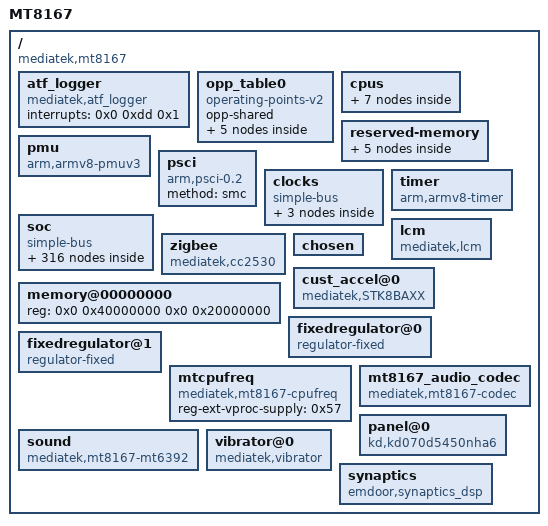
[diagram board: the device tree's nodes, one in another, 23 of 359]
/dts-v1/;

/ {
	model = "MT8167";
	compatible = "mediatek,mt8167";
	interrupt-parent = <0x1>;
	#address-cells = <0x2>;
	#size-cells = <0x2>;

	atf_logger {
		compatible = "mediatek,atf_logger";
		interrupts = <0x0 0xdd 0x1>;
	};

	opp_table0 {
		compatible = "operating-points-v2";
		opp-shared;
		linux,phandle = <0x7>;
		phandle = <0x7>;

		opp00 {
			opp-hz = <0x0 0x23a4c180>;
			opp-microvolt = <0x118c30>;
		};

		opp01 {
			opp-hz = <0x0 0x2c8df1e0>;
			opp-microvolt = <0x118c30>;
		};

		opp02 {
			opp-hz = <0x0 0x3dfd2400>;
			opp-microvolt = <0x124f80>;
		};

		opp03 {
			opp-hz = <0x0 0x47498300>;
			opp-microvolt = <0x1312d0>;
		};

		opp04 {
			opp-hz = <0x0 0x4d7c6d00>;
			opp-microvolt = <0x13d620>;
		};
	};

	cpus {
		#address-cells = <0x1>;
		#size-cells = <0x0>;

		cpu@0 {
			device_type = "cpu";
			compatible = "arm,cortex-a53";
			reg = <0x0>;
			enable-method = "psci";
			cpu-idle-states = <0x2 0x2 0x3 0x3 0x3>;
			clocks = <0x4 0x0 0x5 0x8 0x6 0x0>;
			clock-names = "cpu", "intermediate", "armpll";
			operating-points-v2 = <0x7>;
			clock-frequency = "M|m";
			proc-supply = <0x8>;
			linux,phandle = <0x9>;
			phandle = <0x9>;
		};

		cpu@1 {
			device_type = "cpu";
			compatible = "arm,cortex-a53";
			reg = <0x1>;
			enable-method = "psci";
			cpu-idle-states = <0x2 0x2 0x3 0x3 0x3>;
			clocks = <0x4 0x0 0x5 0x8 0x6 0x0>;
			clock-names = "cpu", "intermediate", "armpll";
			operating-points-v2 = <0x7>;
			clock-frequency = "M|m";
			proc-supply = <0x8>;
			linux,phandle = <0xa>;
			phandle = <0xa>;
		};

		cpu@2 {
			device_type = "cpu";
			compatible = "arm,cortex-a53";
			reg = <0x2>;
			enable-method = "psci";
			cpu-idle-states = <0x2 0x2 0x3 0x3 0x3>;
			clocks = <0x4 0x0 0x5 0x8 0x6 0x0>;
			clock-names = "cpu", "intermediate", "armpll";
			operating-points-v2 = <0x7>;
			clock-frequency = "M|m";
			proc-supply = <0x8>;
			linux,phandle = <0xb>;
			phandle = <0xb>;
		};

		cpu@3 {
			device_type = "cpu";
			compatible = "arm,cortex-a53";
			reg = <0x3>;
			enable-method = "psci";
			cpu-idle-states = <0x2 0x2 0x3 0x3 0x3>;
			clocks = <0x4 0x0 0x5 0x8 0x6 0x0>;
			clock-names = "cpu", "intermediate", "armpll";
			operating-points-v2 = <0x7>;
			clock-frequency = "M|m";
			proc-supply = <0x8>;
			linux,phandle = <0xc>;
			phandle = <0xc>;
		};

		idle-states {
			entry-method = "arm,psci";

			cpu-sleep-0-0 {
				compatible = "arm,idle-state";
				arm,psci-suspend-param = <0x10000>;
				entry-latency-us = <0x258>;
				exit-latency-us = <0x258>;
				min-residency-us = <0x4b0>;
				linux,phandle = <0x3>;
				phandle = <0x3>;
			};

			cluster-sleep-0 {
				compatible = "arm,idle-state";
				arm,psci-suspend-param = <0x2010000>;
				entry-latency-us = <0x320>;
				exit-latency-us = <0x3e8>;
				min-residency-us = <0x7d0>;
				linux,phandle = <0x2>;
				phandle = <0x2>;
			};
		};
	};

	reserved-memory {
		#address-cells = <0x2>;
		#size-cells = <0x2>;
		ranges;

		atf-reserved-memory@43000000 {
			compatible = "mediatek,mt8167-atf-reserved-memory";
			no-map;
			reg = <0x0 0x43000000 0x0 0x30000>;
		};

		ram_console-reserved-memory@44400000 {
			compatible = "mediatek,ram_console";
			reg = <0x0 0x44400000 0x0 0x10000>;
		};

		pstore-reserved-memory@44410000 {
			compatible = "mediatek,pstore";
			reg = <0x0 0x44410000 0x0 0xe0000>;
		};

		minirdump-reserved-memory@444f0000 {
			compatible = "mediatek,minirdump";
			reg = <0x0 0x444f0000 0x0 0x10000>;
		};

		consys-reserve-memory {
			compatible = "mediatek,consys-reserve-memory";
			no-map;
			size = <0x0 0x200000>;
			alignment = <0x0 0x200000>;
		};
	};

	pmu {
		compatible = "arm,armv8-pmuv3";
		interrupts = <0x0 0x4 0x8 0x0 0x5 0x8 0x0 0x6 0x8 0x0 0x7 0x8>;
		interrupt-affinity = <0x9 0xa 0xb 0xc>;
	};

	psci {
		compatible = "arm,psci-0.2";
		method = "smc";
	};

	clocks {
		#address-cells = <0x2>;
		#size-cells = <0x2>;
		compatible = "simple-bus";
		ranges;

		clk26m {
			compatible = "fixed-clock";
			#clock-cells = <0x0>;
			clock-frequency = <0x18cba80>;
		};

		clk32k {
			compatible = "fixed-clock";
			#clock-cells = <0x0>;
			clock-frequency = <0x7d00>;
			linux,phandle = <0xe>;
			phandle = <0xe>;
		};

		dummy26m {
			compatible = "fixed-clock";
			clock-frequency = <0x18cba80>;
			#clock-cells = <0x0>;
		};
	};

	timer {
		compatible = "arm,armv8-timer";
		interrupt-parent = <0xd>;
		interrupts = <0x1 0xd 0xf08 0x1 0xe 0xf08 0x1 0xb 0xf08 0x1 0xa 0xf08>;
		clock-frequency = <0xc65d40>;
	};

	soc {
		#address-cells = <0x2>;
		#size-cells = <0x2>;
		compatible = "simple-bus";
		ranges;

		chipid@08000000 {
			compatible = "mediatek,chipid";
			reg = <0x0 0x8000000 0x0 0x4 0x0 0x8000004 0x0 0x4 0x0 0x8000008 0x0 0x4 0x0 0x800000c 0x0 0x4>;
		};

		topckgen@10000000 {
			compatible = "mediatek,mt8167-topckgen", "syscon";
			reg = <0x0 0x10000000 0x0 0x1000>;
			#clock-cells = <0x1>;
			linux,phandle = <0x5>;
			phandle = <0x5>;
		};

		infracfg@10001000 {
			compatible = "mediatek,mt8167-infracfg", "syscon";
			reg = <0x0 0x10001000 0x0 0x1000>;
			#clock-cells = <0x1>;
			linux,phandle = <0x4>;
			phandle = <0x4>;
		};

		btcvsd@10001000 {
			compatible = "mediatek,audio_bt_cvsd";
			offset = <0xc00 0x2 0xfd0 0xfd4 0xfd8>;
			reg = <0x0 0x10001000 0x0 0x1000 0x0 0x18000000 0x0 0x10000 0x0 0x18080000 0x0 0x8000>;
			interrupts = <0x0 0xc2 0x8>;
		};

		mt_soc_btcvsd_rx_pcm@10001000 {
			compatible = "mediatek,mt_soc_btcvsd_rx_pcm";
		};

		mt_soc_btcvsd_tx_pcm@10001000 {
			compatible = "mediatek,mt_soc_btcvsd_tx_pcm";
		};

		syscfg_pctl_a@10005000 {
			compatible = "mediatek,mt8167-pctl-a-syscfg", "syscon";
			reg = <0x0 0x10005000 0x0 0x1000>;
			linux,phandle = <0xf>;
			phandle = <0xf>;
		};

		toprgu@10007000 {
			compatible = "mediatek,mt8167-wdt", "mediatek,mt6589-wdt";
			reg = <0x0 0x10007000 0x0 0x1000>;
			interrupts = <0x0 0xc6 0x2>;
			#reset-cells = <0x1>;
			linux,phandle = <0x47>;
			phandle = <0x47>;
		};

		timer@10008000 {
			compatible = "mediatek,mt8167-timer", "mediatek,mt6577-timer";
			reg = <0x0 0x10008000 0x0 0x1000>;
			interrupts = <0x0 0x84 0x8>;
			clocks = <0x5 0x32 0xe 0x5 0x5a>;
			clock-names = "clk13m", "clk32k", "bus";
		};

		pinctrl@10005000 {
			compatible = "mediatek,mt8167-pinctrl";
			reg = <0x0 0x1000b000 0x0 0x1000>;
			mediatek,pctl-regmap = <0xf>;
			pins-are-numbered;
			gpio-controller;
			#gpio-cells = <0x2>;
			interrupt-controller;
			#interrupt-cells = <0x2>;
			interrupts = <0x0 0x86 0x4>;
			pinctrl-names = "default";
			pinctrl-0 = <0x10>;
			linux,phandle = <0x12>;
			phandle = <0x12>;

			uart0gpiodefault {
				linux,phandle = <0x17>;
				phandle = <0x17>;
			};

			uart0_rx_set {
				linux,phandle = <0x18>;
				phandle = <0x18>;

				pins_cmd_dat {
					pinmux = <0x3e01>;
				};
			};

			uart0_rx_clear {
				linux,phandle = <0x19>;
				phandle = <0x19>;

				pins_cmd_dat {
					pinmux = <0x3e00>;
					slew-rate = <0x1>;
					output-high;
				};
			};

			uart0_tx_set {
				linux,phandle = <0x1a>;
				phandle = <0x1a>;

				pins_cmd_dat {
					pinmux = <0x3f01>;
				};
			};

			uart0_tx_clear {
				linux,phandle = <0x1b>;
				phandle = <0x1b>;

				pins_cmd_dat {
					pinmux = <0x3f00>;
					slew-rate = <0x1>;
					output-high;
				};
			};

			uart1gpiodefault {
				linux,phandle = <0x1c>;
				phandle = <0x1c>;
			};

			uart1_rx_set {
				linux,phandle = <0x1d>;
				phandle = <0x1d>;

				pins_cmd_dat {
					pinmux = <0x4001>;
				};
			};

			uart1_rx_clear {
				linux,phandle = <0x1e>;
				phandle = <0x1e>;

				pins_cmd_dat {
					pinmux = <0x4000>;
					slew-rate = <0x1>;
					output-high;
				};
			};

			uart1_tx_set {
				linux,phandle = <0x1f>;
				phandle = <0x1f>;

				pins_cmd_dat {
					pinmux = <0x4101>;
				};
			};

			uart1_tx_clear {
				linux,phandle = <0x20>;
				phandle = <0x20>;

				pins_cmd_dat {
					pinmux = <0x4100>;
					slew-rate = <0x1>;
					output-high;
				};
			};

			uart2gpiodefault {
				linux,phandle = <0x21>;
				phandle = <0x21>;
			};

			uart2_rx_set {
				linux,phandle = <0x22>;
				phandle = <0x22>;

				pins_cmd_dat {
					pinmux = <0x2201>;
				};
			};

			uart2_rx_clear {
				linux,phandle = <0x23>;
				phandle = <0x23>;

				pins_cmd_dat {
					pinmux = <0x2200>;
					slew-rate = <0x1>;
					output-high;
				};
			};

			uart2_tx_set {
				linux,phandle = <0x24>;
				phandle = <0x24>;

				pins_cmd_dat {
					pins = <0x2301>;
				};
			};

			uart2_tx_clear {
				linux,phandle = <0x25>;
				phandle = <0x25>;

				pins_cmd_dat {
					pinmux = <0x2300>;
					slew-rate = <0x1>;
					output-high;
				};
			};

			pinconf_default {
				linux,phandle = <0x10>;
				phandle = <0x10>;

				pins_cmd_dat {
					pinmux = <0xe03 0xf03 0x1003 0x4406 0x4506 0x4606 0x3701 0x3801 0x3901 0x1103>;
					bias-pull-up;
				};
			};

			audiodefault {
				linux,phandle = <0x5b>;
				phandle = <0x5b>;

				pins_cmd_dat {
					pins = <0x3200>;
					slew-rate = <0x1>;
					output-low;
				};
			};

			audexampon {
				linux,phandle = <0x5c>;
				phandle = <0x5c>;

				pins_cmd_dat {
					pins = <0x3200>;
					slew-rate = <0x1>;
					output-high;
				};
			};

			audexampoff {
				linux,phandle = <0x5d>;
				phandle = <0x5d>;

				pins_cmd_dat {
					pins = <0x3200>;
					slew-rate = <0x1>;
					output-low;
				};
			};

			audi2s1mode0 {
			};

			audi2s1mode1 {
			};

			pmicclkmode0 {
			};

			pmicclkmode1 {
			};

			dspdefault {
				linux,phandle = <0x5e>;
				phandle = <0x5e>;

				pins_cmd_dat {
					pins = <0x4700>;
					slew-rate = <0x1>;
					output-high;
				};
			};

			dsp_pins_rst_high {
				linux,phandle = <0x5f>;
				phandle = <0x5f>;

				pins_cmd_dat {
					pins = <0x4900>;
					slew-rate = <0x1>;
					output-high;
				};
			};

			dsp_pins_rst_low {
				linux,phandle = <0x60>;
				phandle = <0x60>;

				pins_cmd_dat {
					pins = <0x4900>;
					slew-rate = <0x1>;
					output-low;
				};
			};

			dsp_pins_pewr_high {
				linux,phandle = <0x61>;
				phandle = <0x61>;

				pins_cmd_dat {
					pins = <0x1400>;
					slew-rate = <0x1>;
					output-high;
				};
			};

			dsp_pins_pwr_low {
				linux,phandle = <0x62>;
				phandle = <0x62>;

				pins_cmd_dat {
					pins = <0x1400>;
					slew-rate = <0x1>;
					output-low;
				};
			};

			led_pins_pwr_high {
				linux,phandle = <0x63>;
				phandle = <0x63>;

				pins_cmd_dat {
					pins = <0x3300>;
					slew-rate = <0x1>;
					output-high;
				};
			};

			led_pins_pwr_low {
				linux,phandle = <0x64>;
				phandle = <0x64>;

				pins_cmd_dat {
					pins = <0x3300>;
					slew-rate = <0x1>;
					output-low;
				};
			};

			camdefault {
				linux,phandle = <0x3e>;
				phandle = <0x3e>;

				pins_cmd_dat {
					pinmux = <0x6601 0x6701 0x5e01 0x5f01 0x6001 0x6101 0x6201 0x6301>;
				};
			};

			cam0@0 {
				linux,phandle = <0x3f>;
				phandle = <0x3f>;

				pins_cmd_dat {
					pins = <0x3100>;
					slew-rate = <0x1>;
					output-low;
				};
			};

			cam0@1 {
				linux,phandle = <0x40>;
				phandle = <0x40>;

				pins_cmd_dat {
					pins = <0x3100>;
					slew-rate = <0x1>;
					output-high;
				};
			};

			cam0@2 {
				linux,phandle = <0x41>;
				phandle = <0x41>;

				pins_cmd_dat {
					pins = <0x3000>;
					slew-rate = <0x1>;
					output-low;
				};
			};

			cam0@3 {
				linux,phandle = <0x42>;
				phandle = <0x42>;

				pins_cmd_dat {
					pins = <0x3000>;
					slew-rate = <0x1>;
					output-high;
				};
			};

			cam1@0 {
				linux,phandle = <0x43>;
				phandle = <0x43>;

				pins_cmd_dat {
					pins = <0x3100>;
					slew-rate = <0x1>;
					output-low;
				};
			};

			cam1@1 {
				linux,phandle = <0x44>;
				phandle = <0x44>;

				pins_cmd_dat {
					pins = <0x3100>;
					slew-rate = <0x1>;
					output-high;
				};
			};

			cam1@2 {
				linux,phandle = <0x45>;
				phandle = <0x45>;

				pins_cmd_dat {
					pins = <0x2b00>;
					slew-rate = <0x1>;
					output-low;
				};
			};

			cam1@3 {
				linux,phandle = <0x46>;
				phandle = <0x46>;

				pins_cmd_dat {
					pins = <0x2b00>;
					slew-rate = <0x1>;
					output-high;
				};
			};

			cam_pin_mclk {

				pins_cmd_dat {
					pinmux = <0x6601 0x6701 0x5a02 0x5b02 0x5c02 0x5d02 0x5e02 0x5f02 0x6002 0x6102 0x6202 0x6302>;
				};
			};

			cam_pin_pclk {

				pins_cmd_dat {
					pins = <0x6701>;
				};
			};

			cam_pin_gpio90 {

				pins_cmd_dat {
					pins = <0x5a02>;
				};
			};

			cam_pin_gpio91 {

				pins_cmd_dat {
					pins = <0x5b02>;
				};
			};

			cam_pin_gpio92 {

				pins_cmd_dat {
					pins = <0x5c02>;
				};
			};

			cam_pin_gpio93 {

				pins_cmd_dat {
					pins = <0x5d02>;
				};
			};

			cam_pin_gpio94 {

				pins_cmd_dat {
					pins = <0x5e02>;
				};
			};

			cam_pin_gpio95 {

				pins_cmd_dat {
					pins = <0x5f02>;
				};
			};

			cam_pin_gpio96 {

				pins_cmd_dat {
					pins = <0x6002>;
				};
			};

			cam_pin_gpio97 {

				pins_cmd_dat {
					pins = <0x6102>;
				};
			};

			cam_pin_gpio98 {

				pins_cmd_dat {
					pins = <0x6202>;
				};
			};

			cam_pin_gpio99 {

				pins_cmd_dat {
					pins = <0x6302>;
				};
			};

			default {
				linux,phandle = <0x48>;
				phandle = <0x48>;
			};

			eint0default {
				linux,phandle = <0x4f>;
				phandle = <0x4f>;

				pins_cmd_dat {
					pins = <0x6400>;
					slew-rate = <0x0>;
					bias-disable;
				};
			};

			eint@0 {
				linux,phandle = <0x50>;
				phandle = <0x50>;

				pins_cmd_dat {
					pins = <0x6400>;
					slew-rate = <0x0>;
					bias-disable;
				};
			};

			eintoutput0 {
				linux,phandle = <0x51>;
				phandle = <0x51>;

				pins_cmd_dat {
					pins = <0x6400>;
					slew-rate = <0x1>;
					output-low;
				};
			};

			eintoutput1 {
				linux,phandle = <0x52>;
				phandle = <0x52>;

				pins_cmd_dat {
					pins = <0x6400>;
					slew-rate = <0x1>;
					output-high;
				};
			};

			rstoutput0 {
				linux,phandle = <0x53>;
				phandle = <0x53>;

				pins_cmd_dat {
					pins = <0x6500>;
					slew-rate = <0x1>;
					output-low;
				};
			};

			rstoutput1 {
				linux,phandle = <0x54>;
				phandle = <0x54>;

				pins_cmd_dat {
					pins = <0x6500>;
					slew-rate = <0x1>;
					output-high;
				};
			};

			hwen_high {
			};

			hwen_low {
			};

			gpslna@0 {
				linux,phandle = <0x49>;
				phandle = <0x49>;
			};

			gpslna@1 {
				linux,phandle = <0x4a>;
				phandle = <0x4a>;
			};

			gpslna@2 {
				linux,phandle = <0x4b>;
				phandle = <0x4b>;
			};

			hdmi_pins_default {
				linux,phandle = <0x35>;
				phandle = <0x35>;
			};

			hdmi_pins_hpd {
				linux,phandle = <0x36>;
				phandle = <0x36>;
			};

			i2c0@0 {
				linux,phandle = <0x26>;
				phandle = <0x26>;

				pins1 {
					pinmux = <0x3a01 0x3b01>;
					bias-disable;
				};
			};

			i2c1@0 {
				linux,phandle = <0x27>;
				phandle = <0x27>;

				pins1 {
					pinmux = <0x3401 0x3501>;
					bias-disable;
				};
			};

			i2c2@0 {
				linux,phandle = <0x28>;
				phandle = <0x28>;

				pins1 {
					pinmux = <0x3c01 0x3d01>;
					bias-disable;
				};
			};

			dpi_pins_default {
				linux,phandle = <0x59>;
				phandle = <0x59>;

				pins_cmd_dat {
					pinmux = <0x2302 0x1902 0x1802 0x2 0x2602 0x2702 0x2502 0x2402 0x2202 0x702 0x806 0x906 0xa06 0xb05 0xc05 0x102 0x202 0x302 0x402 0x502 0x602 0xd05>;
					drive-strength = <0x2>;
				};
			};

			mmc0default {
				linux,phandle = <0x31>;
				phandle = <0x31>;

				pins_cmd_dat {
					pinmux = <0x7801 0x7701 0x7601 0x7501 0x7101 0x7001 0x6f01 0x6e01 0x7301>;
					input-enable;
					bias-pull-up;
				};

				pins_clk {
					pinmux = <0x7401>;
					bias-pull-down;
				};

				pins_rst {
					pinmux = <0x7201>;
					bias-pull-up;
				};
			};

			mmc0@0 {
				linux,phandle = <0x32>;
				phandle = <0x32>;

				pins_cmd_dat {
					pinmux = <0x7801 0x7701 0x7601 0x7501 0x7101 0x7001 0x6f01 0x6e01 0x7301>;
					input-enable;
					drive-strength = <0x6>;
					bias-pull-up = <0x65>;
				};

				pins_clk {
					pinmux = <0x7401>;
					drive-strength = <0x8>;
					bias-pull-down = <0x66>;
				};

				pins_rst {
					pinmux = <0x7201>;
					bias-pull-up;
				};
			};

			drvvbus_init {
				linux,phandle = <0x2c>;
				phandle = <0x2c>;

				pins_cmd_dat {
					pins = <0x4100>;
					output-low;
				};
			};

			drvvbus_high {
				linux,phandle = <0x2e>;
				phandle = <0x2e>;

				pins_cmd_dat {
					pins = <0x4100>;
					slew-rate = <0x1>;
					output-high;
				};
			};

			drvvbus_low {
				linux,phandle = <0x2d>;
				phandle = <0x2d>;

				pins_cmd_dat {
					pins = <0x4100>;
					slew-rate = <0x1>;
					output-low;
				};
			};

			iddig_irq_init {
				linux,phandle = <0x2b>;
				phandle = <0x2b>;

				pins_cmd_dat {
					pins = <0x2902>;
					slew-rate = <0x0>;
					bias-pull-up = <0x0>;
				};
			};
		};

		dramco@10207000 {
			compatible = "mediatek,mt8167-dramco";
			reg = <0x0 0x10207000 0x0 0x1000>;
		};

		scpsys@10006000 {
			compatible = "mediatek,mt8167-scpsys", "syscon";
			#power-domain-cells = <0x1>;
			reg = <0x0 0x10006000 0x0 0x1000>;
			interrupts = <0x0 0x80 0x8 0x0 0x81 0x8 0x0 0x82 0x8 0x0 0x83 0x8>;
			infracfg = <0x4>;
			clocks = <0x5 0x82 0x5 0x83 0x5 0x42 0x5 0x7f>;
			clock-names = "axi_mfg", "mfg", "mm", "vdec";
			mediatek,pwrap-regmap = <0x11>;
			linux,phandle = <0x30>;
			phandle = <0x30>;
		};

		hacc@1000a000 {
			compatible = "mediatek,hacc";
			reg = <0x0 0x1000a000 0x0 0x1000>;
			clocks = <0x5 0x57 0x5 0x66>;
			clock-names = "main", "second";
		};

		pwrap@1000f000 {
			compatible = "mediatek,mt8167-pwrap";
			reg = <0x0 0x1000f000 0x0 0x1000>;
			reg-names = "pwrap";
			interrupts = <0x0 0xcc 0x8>;
			clocks = <0x5 0x5e 0x5 0x56>;
			clock-names = "spi", "wrap";
			status = "okay";
			linux,phandle = <0x11>;
			phandle = <0x11>;

			mt6392 {
				compatible = "mediatek,mt6392";
				mediatek,system-power-controller;
				interrupt-parent = <0x12>;
				interrupts = <0x1c 0x4>;
				interrupt-controller;
				#interrupt-cells = <0x2>;
				linux,phandle = <0x55>;
				phandle = <0x55>;

				mt6392keys {
					compatible = "mediatek,mt6392-keys";
					mediatek,pwrkey-code = <0x74>;
					mediatek,homekey-code = <0x72>;
					mediatek,long-press-mode = <0x0>;
					mediatek,long-press-duration = <0x0>;
				};

				mt6392pmic {
					compatible = "mediatek,mt6392-pmic";
				};

				mt6392regulator {
					compatible = "mediatek,mt6392-regulator";

					buck_vproc {
						regulator-name = "vproc";
						regulator-min-microvolt = <0xaae60>;
						regulator-max-microvolt = <0x149970>;
						regulator-ramp-delay = <0x30d4>;
						regulator-always-on;
						regulator-boot-on;
						linux,phandle = <0x8>;
						phandle = <0x8>;
					};

					buck_vsys {
						regulator-name = "vsys";
						regulator-min-microvolt = <0x155cc0>;
						regulator-max-microvolt = <0x2d95ec>;
						regulator-ramp-delay = <0x61a8>;
						regulator-always-on;
						regulator-boot-on;
					};

					buck_vcore {
						regulator-name = "vcore";
						regulator-min-microvolt = <0xaae60>;
						regulator-max-microvolt = <0x149970>;
						regulator-ramp-delay = <0x30d4>;
						regulator-always-on;
						regulator-boot-on;
						linux,phandle = <0x2a>;
						phandle = <0x2a>;
					};

					ldo_vxo22 {
						regulator-name = "vxo22";
						regulator-min-microvolt = <0x2191c0>;
						regulator-max-microvolt = <0x2191c0>;
						regulator-enable-ramp-delay = <0x6e>;
						regulator-always-on;
						regulator-boot-on;
					};

					ldo_vaud22 {
						regulator-name = "vaud22";
						regulator-min-microvolt = <0x1b7740>;
						regulator-max-microvolt = <0x2191c0>;
						regulator-enable-ramp-delay = <0x108>;
						regulator-always-on;
						regulator-boot-on;
					};

					ldo_vcama {
						regulator-name = "vcama";
						regulator-min-microvolt = <0x2ab980>;
						regulator-max-microvolt = <0x2ab980>;
						regulator-enable-ramp-delay = <0x108>;
						linux,phandle = <0x3a>;
						phandle = <0x3a>;
					};

					ldo_vaud28 {
						regulator-name = "vaud28";
						regulator-min-microvolt = <0x2ab980>;
						regulator-max-microvolt = <0x2ab980>;
						regulator-enable-ramp-delay = <0x108>;
						regulator-always-on;
						regulator-boot-on;
					};

					ldo_vadc18 {
						regulator-name = "vadc18";
						regulator-min-microvolt = <0x1b7740>;
						regulator-max-microvolt = <0x1b7740>;
						regulator-enable-ramp-delay = <0x108>;
						regulator-always-on;
						regulator-boot-on;
					};

					ldo_vcn35 {
						regulator-name = "vcn35";
						regulator-min-microvolt = <0x325aa0>;
						regulator-max-microvolt = <0x36ee80>;
						regulator-enable-ramp-delay = <0x108>;
						linux,phandle = <0x4d>;
						phandle = <0x4d>;
					};

					ldo_vio28 {
						regulator-name = "vio28";
						regulator-min-microvolt = <0x2ab980>;
						regulator-max-microvolt = <0x2ab980>;
						regulator-enable-ramp-delay = <0x108>;
						regulator-always-on;
						regulator-boot-on;
					};

					ldo_vusb {
						regulator-name = "vusb";
						regulator-min-microvolt = <0x325aa0>;
						regulator-max-microvolt = <0x325aa0>;
						regulator-enable-ramp-delay = <0x108>;
						regulator-always-on;
						regulator-boot-on;
						linux,phandle = <0x2f>;
						phandle = <0x2f>;
					};

					ldo_vmc {
						regulator-name = "vmc";
						regulator-min-microvolt = <0x1b7740>;
						regulator-max-microvolt = <0x325aa0>;
						regulator-enable-ramp-delay = <0x108>;
						regulator-boot-on;
					};

					ldo_vmch {
						regulator-name = "vmch";
						regulator-min-microvolt = <0x2dc6c0>;
						regulator-max-microvolt = <0x325aa0>;
						regulator-enable-ramp-delay = <0x108>;
						regulator-boot-on;
					};

					ldo_vemc3v3 {
						regulator-name = "vemc3v3";
						regulator-min-microvolt = <0x2dc6c0>;
						regulator-max-microvolt = <0x325aa0>;
						regulator-enable-ramp-delay = <0x108>;
						regulator-boot-on;
						linux,phandle = <0x33>;
						phandle = <0x33>;
					};

					ldo_vgp1 {
						regulator-name = "vgp1";
						regulator-min-microvolt = <0x124f80>;
						regulator-max-microvolt = <0x325aa0>;
						regulator-enable-ramp-delay = <0x108>;
						regulator-boot-on;
						linux,phandle = <0x4e>;
						phandle = <0x4e>;
					};

					ldo_vgp2 {
						regulator-name = "vgp2";
						regulator-min-microvolt = <0x124f80>;
						regulator-max-microvolt = <0x325aa0>;
						regulator-enable-ramp-delay = <0x108>;
						linux,phandle = <0x5a>;
						phandle = <0x5a>;
					};

					ldo_vcn18 {
						regulator-name = "vcn18";
						regulator-min-microvolt = <0x1b7740>;
						regulator-max-microvolt = <0x1b7740>;
						regulator-enable-ramp-delay = <0x108>;
						linux,phandle = <0x4c>;
						phandle = <0x4c>;
					};

					ldo_vcamaf {
						regulator-name = "vcamaf";
						regulator-min-microvolt = <0x325aa0>;
						regulator-max-microvolt = <0x325aa0>;
						regulator-enable-ramp-delay = <0x108>;
						regulator-always-on;
						regulator-boot-on;
						linux,phandle = <0x3d>;
						phandle = <0x3d>;
					};

					ldo_vm {
						regulator-name = "vm";
						regulator-min-microvolt = <0x12ebc0>;
						regulator-max-microvolt = <0x1535b0>;
						regulator-enable-ramp-delay = <0x108>;
						regulator-always-on;
						regulator-boot-on;
					};

					ldo_vio18 {
						regulator-name = "vio18";
						regulator-min-microvolt = <0x1b7740>;
						regulator-max-microvolt = <0x1b7740>;
						regulator-enable-ramp-delay = <0x108>;
						regulator-always-on;
						regulator-boot-on;
						linux,phandle = <0x34>;
						phandle = <0x34>;
					};

					ldo_vcamd {
						regulator-name = "vcamd";
						regulator-min-microvolt = <0x124f80>;
						regulator-max-microvolt = <0x1b7740>;
						regulator-enable-ramp-delay = <0x108>;
						linux,phandle = <0x3b>;
						phandle = <0x3b>;
					};

					ldo_vcamio {
						regulator-name = "vcamio";
						regulator-min-microvolt = <0x1b7740>;
						regulator-max-microvolt = <0x1b7740>;
						regulator-enable-ramp-delay = <0x108>;
						linux,phandle = <0x3c>;
						phandle = <0x3c>;
					};

					ldo_vm25 {
						regulator-name = "vm25";
						regulator-min-microvolt = <0x2625a0>;
						regulator-max-microvolt = <0x2625a0>;
						regulator-enable-ramp-delay = <0x108>;
						regulator-always-on;
						regulator-boot-on;
					};

					ldo_vefuse {
						regulator-name = "vefuse";
						regulator-min-microvolt = <0x1b7740>;
						regulator-max-microvolt = <0x1e8480>;
						regulator-enable-ramp-delay = <0x108>;
					};
				};

				pinctrl@c000 {
					compatible = "mediatek,mt6392-pinctrl";
					pins-are-numbered;
					gpio-controller;
					#gpio-cells = <0x2>;
				};

				typec {
					compatible = "mediatek,mt6392-typec";
					status = "disabled";
				};
			};
		};

		devapc_ao@10010000 {
			compatible = "mediatek,mt8167-devapc_ao";
			reg = <0x0 0x10010000 0x0 0x1000>;
		};

		keypad@10002000 {
			compatible = "mediatek,mt8167-keypad";
			reg = <0x0 0x10002000 0x0 0x1000>;
			interrupts = <0x0 0x95 0x2>;
			mediatek,kpd-key-debounce = <0x400>;
			mediatek,kpd-sw-pwrkey = <0x74>;
			mediatek,kpd-hw-pwrkey = <0x8>;
			mediatek,kpd-sw-rstkey = <0x0>;
			mediatek,kpd-hw-rstkey = <0x11>;
			mediatek,kpd-use-extend-type = <0x0>;
			mediatek,kpd-hw-map-num = <0x48>;
			mediatek,kpd-hw-init-map = <0x73 0x0 0x0 0x0 0x0 0x0 0x0 0x0 0x0 0x0 0x0 0x0 0x0 0x0 0x0 0x0 0x0 0x0 0x0 0x0 0x0 0x0 0x0 0x0 0x0 0x0 0x0 0x0 0x0 0x0 0x0 0x0 0x0 0x0 0x0 0x0 0x0 0x0 0x0 0x0 0x0 0x0 0x0 0x0 0x0 0x0 0x0 0x0 0x0 0x0 0x0 0x0 0x0 0x0 0x0 0x0 0x0 0x0 0x0 0x0 0x0 0x0 0x0 0x0 0x0 0x0 0x0 0x0 0x0 0x0 0x0 0x0>;
			mediatek,kpd-pwrkey-eint-gpio = <0x0>;
			mediatek,kpd-pwkey-gpio-din = <0x0>;
			mediatek,kpd-hw-dl-key0 = <0x0>;
			mediatek,kpd-hw-dl-key1 = <0x11>;
			mediatek,kpd-hw-dl-key2 = <0x8>;
			mediatek,kpd-hw-recovery-key = <0x11>;
			mediatek,kpd-hw-factory-key = <0x0>;
		};

		apmixedsys@10018000 {
			compatible = "mediatek,mt8167-apmixedsys", "syscon";
			reg = <0x0 0x10018000 0x0 0x710>;
			#clock-cells = <0x1>;
			linux,phandle = <0x6>;
			phandle = <0x6>;
		};

		fhctl@10018f00 {
			compatible = "mediatek,mt8167-fhctl";
			reg = <0x0 0x10018f00 0x0 0x100>;
		};

		accdet@1001b000 {
			compatible = "mediatek,mt8167-accdet";
			reg = <0x0 0x1001b000 0x0 0x1000>;
			status = "okay";
			mediatek,apmixedsys-regmap = <0x6>;
			interrupts-extended = <0x1 0x0 0x98 0x8 0x12 0x13 0x4>;
			interrupts = <0x13 0x4>;
			eint-debounce = <0x3e800>;
			accdet-gpio = <0x12 0x13 0x0>;
			accdet-mic-vol = <0x0>;
			headset-mode-setting = <0x500 0x500 0x1 0x1f0 0x800 0x800 0x20>;
			accdet-plugout-debounce = <0x14>;
			accdet-mic-mode = <0x1>;
			headset-four-key-threshold = <0x15e 0x1a4 0x352 0x5dc>;
		};

		mcucfg@10200000 {
			compatible = "mediatek,mt8167-mcucfg", "mediatek,mcucfg", "syscon";
			reg = <0x0 0x10200000 0x0 0x2000>;
		};

		intpol-controller@10200620 {
			compatible = "mediatek,mt8167-sysirq", "mediatek,mt6577-sysirq";
			interrupt-controller;
			#interrupt-cells = <0x3>;
			interrupt-parent = <0xd>;
			reg = <0x0 0x10200620 0x0 0x20>;
			linux,phandle = <0x1>;
			phandle = <0x1>;
		};

		emi@10205000 {
			compatible = "mediatek,mt8167-emi", "mediatek,emi";
			reg = <0x0 0x10205000 0x0 0x1000>;
			interrupts = <0x0 0x74 0x4>;
		};

		m4u@10203000 {
			cell-index = <0x0>;
			compatible = "mediatek,mt8167-m4u";
			reg = <0x0 0x10203000 0x0 0x1000>;
			mediatek,larbs = <0x13 0x14 0x15>;
			interrupts = <0x0 0x79 0x8>;
			#iommu-cells = <0x1>;
			linux,phandle = <0x56>;
			phandle = <0x56>;
		};

		sys_cirq@10202000 {
			compatible = "mediatek,mt8167-sys_cirq", "mediatek,mt6735-sys_cirq", "mediatek,sys_cirq";
			reg = <0x0 0x10202000 0x0 0x1000>;
			interrupts = <0x0 0xda 0x8>;
			mediatek,cirq_num = <0x93>;
			mediatek,spi_start_offset = <0x48>;
		};

		devapc@10204000 {
			compatible = "mediatek,mt8167-devapc";
			reg = <0x0 0x10204000 0x0 0x1000>;
			interrupts = <0x0 0x72 0x8>;
		};

		systracker@1020b000 {
			compatible = "mediatek,bus_dbg-v2";
			reg = <0x0 0x1020b000 0x0 0x1000>;
			interrupts = <0x0 0x7b 0x8>;
		};

		dramc_nao@10206000 {
			compatible = "mediatek,mt8167-dramc_nao", "mediatek,dramc_nao";
			reg = <0x0 0x10206000 0x0 0x1000>;
		};

		xo@10210000 {
			compatible = "mediatek,mt8167-xo";
			reg = <0x0 0x10210000 0x0 0x1000>;
			clocks = <0x5 0x7a 0x5 0x8c>;
			clock-names = "bsi", "rgbsi";
		};

		ddrphy@10211000 {
			compatible = "mediatek,mt8167-ddrphy", "mediatek,ddrphy";
			reg = <0x0 0x10211000 0x0 0x1000>;
		};

		gce@1020a000 {
			compatible = "mediatek,mt8167-gce";
			reg = <0x0 0x1020a000 0x0 0x1000>;
			interrupts = <0x0 0x7d 0x8 0x0 0x7e 0x8>;
			disp_mutex_reg = <0x14015000 0x1000>;
			g3d_config_base = <0x13000000 0x0 0xffff0000>;
			mmsys_config_base = <0x14000000 0x1 0xffff0000>;
			disp_dither_base = <0x14010000 0x2 0xffff0000>;
			mm_na_base = <0x14020000 0x3 0xffff0000>;
			imgsys_base = <0x15000000 0x4 0xffff0000>;
			vdec_gcon_base = <0x16000000 0x5 0xffff0000>;
			venc_gcon_base = <0x17000000 0x6 0xffff0000>;
			conn_peri_base = <0x18000000 0x7 0xffff0000>;
			topckgen_base = <0x10000000 0x8 0xffff0000>;
			kp_base = <0x10010000 0x9 0xffff0000>;
			scp_sram_base = <0x10020000 0xa 0xffff0000>;
			infra_na3_base = <0x10030000 0xb 0xffff0000>;
			infra_na4_base = <0x10040000 0xc 0xffff0000>;
			scp_base = <0x10050000 0xd 0xffff0000>;
			mcucfg_base = <0x10200000 0xe 0xffff0000>;
			gcpu_base = <0x1020d000 0xf 0xffff0000>;
			usb0_base = <0x11200000 0x10 0xffff0000>;
			usb_sif_base = <0x11210000 0x11 0xffff0000>;
			audio_base = <0x11220000 0x12 0xffff0000>;
			msdc0_base = <0x11230000 0x13 0xffff0000>;
			msdc1_base = <0x11240000 0x14 0xffff0000>;
			msdc2_base = <0x11250000 0x15 0xffff0000>;
			msdc3_base = <0x11260000 0x16 0xffff0000>;
			pwm_sw_base = <0x1100f000 0x63 0xfffff000>;
			mdp_rdma0_sof = <0x0>;
			mdp_rsz0_sof = <0x1>;
			mdp_rsz1_sof = <0x2>;
			mdp_tdshp_sof = <0x3>;
			mdp_wdma_sof = <0x4>;
			mdp_wrot_sof = <0x5>;
			disp_ovl0_sof = <0x6>;
			disp_rdma0_sof = <0x8>;
			disp_rdma1_sof = <0x9>;
			disp_wdma0_sof = <0xa>;
			disp_ccorr_sof = <0xb>;
			disp_color_sof = <0xc>;
			disp_aal_sof = <0xd>;
			disp_gamma_sof = <0xe>;
			disp_dither_sof = <0xf>;
			disp_ufoe_sof = <0x10>;
			disp_pwm0_sof = <0x11>;
			mdp_rdma0_frame_done = <0x12>;
			mdp_rsz0_frame_done = <0x13>;
			mdp_rsz1_frame_done = <0x14>;
			mdp_tdshp_frame_done = <0x15>;
			mdp_wdma_frame_done = <0x16>;
			mdp_wrot_write_frame_done = <0x17>;
			mdp_wrot_read_frame_done = <0x18>;
			disp_ovl0_frame_done = <0x19>;
			disp_rdma0_frame_done = <0x1b>;
			disp_rdma1_frame_done = <0x1c>;
			disp_wdma0_frame_done = <0x1d>;
			disp_ccorr_frame_done = <0x1e>;
			disp_color_frame_done = <0x1f>;
			disp_aal_frame_done = <0x20>;
			disp_gamma_frame_done = <0x21>;
			disp_dither_frame_done = <0x22>;
			disp_ufoe_frame_done = <0x23>;
			disp_dpi0_frame_done = <0x24>;
			disp_dpi1_frame_done = <0x25>;
			stream_done_0 = <0x26>;
			stream_done_1 = <0x27>;
			stream_done_2 = <0x28>;
			stream_done_3 = <0x29>;
			stream_done_4 = <0x2a>;
			stream_done_5 = <0x2b>;
			stream_done_6 = <0x2c>;
			stream_done_7 = <0x2d>;
			stream_done_8 = <0x2e>;
			stream_done_9 = <0x2f>;
			buf_underrun_event_0 = <0x30>;
			buf_underrun_event_1 = <0x31>;
			isp_frame_done_p2_1 = <0x42>;
			isp_frame_done_p2_0 = <0x43>;
			seninf_cam0_fifo_full = <0x49>;
			apxgpt2_count = <0x10008028>;
			clocks = <0x5 0x64 0x16 0x0 0x16 0x1 0x16 0x2 0x16 0x3 0x16 0x4 0x16 0x5 0x16 0x6 0x16 0x8 0x16 0x7>;
			clock-names = "MT_CG_INFRA_GCE", "MT_CG_DISP0_SMI_COMMON", "MT_CG_DISP0_SMI_LARB0", "MT_CG_DISP0_CAM_MDP", "MT_CG_DISP0_MDP_RDMA", "MT_CG_DISP0_MDP_RSZ0", "MT_CG_DISP0_MDP_RSZ1", "MT_CG_DISP0_MDP_TDSHP", "MT_CG_DISP0_MDP_WROT", "MT_CG_DISP0_MDP_WDMA";
		};

		interrupt-controller@10310000 {
			compatible = "arm,gic-400";
			interrupt-controller;
			#interrupt-cells = <0x3>;
			interrupt-parent = <0xd>;
			reg = <0x0 0x10310000 0x0 0x1000 0x0 0x10320000 0x0 0x1000 0x0 0x10340000 0x0 0x2000 0x0 0x10360000 0x0 0x2000>;
			interrupts = <0x1 0x9 0xf04>;
			linux,phandle = <0xd>;
			phandle = <0xd>;
		};

		btif_tx@11000380 {
			compatible = "mediatek,btif_tx";
			reg = <0x0 0x11000380 0x0 0x80>;
			interrupts = <0x0 0x5e 0x8>;
		};

		btif_rx@11000400 {
			compatible = "mediatek,btif_rx";
			reg = <0x0 0x11000400 0x0 0x80>;
			interrupts = <0x0 0x5f 0x8>;
		};

		nfi@11001000 {
			compatible = "mediatek,mt8167-nfi";
			reg = <0x0 0x11001000 0x0 0x1000>;
			interrupts = <0x0 0x57 0x8>;
			clocks = <0x5 0x63 0x5 0x49 0x5 0x48 0x5 0x8e 0x5 0x55 0x5 0x3a 0x5 0xad 0x5 0xac 0x5 0xce 0x5 0xcd 0x5 0xa1 0x5 0x31 0x5 0x9 0x5 0x11 0x5 0xf 0x5 0x15 0x5 0xa 0x5 0x12 0x5 0x10>;
			clock-names = "nfi_hclk", "nfiecc_bclk", "nfi_bclk", "nfi_rgecc", "nfi_2xclk", "nfi_1xclk", "nfi_1xpad_sel", "nfi_2xpad_sel", "nfiecc_sel", "nfiecc_csw_sel", "infra_ahb", "clk_26m", "main_d4", "main_d5", "main_d6", "main_d7", "main_d8", "main_d10", "main_d12";
			status = "disabled";
		};

		nfiecc@11002000 {
			compatible = "mediatek,mt8167-nfiecc";
			reg = <0x0 0x11002000 0x0 0x1000>;
			interrupts = <0x0 0x56 0x8>;
			status = "disabled";
		};

		auxadc@11003000 {
			compatible = "mediatek,mt8167-auxadc";
			reg = <0x0 0x11003000 0x0 0x1000>;
			interrupts = <0x0 0x4b 0x2>;
			clocks = <0x5 0x5f 0x5 0x47 0x5 0x51 0x5 0x60>;
			clock-names = "auxadc-main", "auxadc1", "auxadc2", "auxadc-tp";
			linux,phandle = <0x29>;
			phandle = <0x29>;
		};

		uart0@11005000 {
			cell-index = <0x0>;
			compatible = "mediatek,mt8167-uart";
			reg = <0x0 0x11005000 0x0 0x1000 0x0 0x11000480 0x0 0x80 0x0 0x11000500 0x0 0x80>;
			interrupts = <0x0 0x54 0x8 0x0 0x60 0x8 0x0 0x61 0x8>;
			clock-frequency = <0x18cba80>;
			clock-div = <0x1>;
			clocks = <0x5 0x4c 0x5 0x44>;
			clock-names = "uart0-main", "uart-apdma";
			pinctrl-names = "uart0_gpio_default", "uart0_rx_set", "uart0_rx_clear", "uart0_tx_set", "uart0_tx_clear";
			pinctrl-0 = <0x17>;
			pinctrl-1 = <0x18>;
			pinctrl-2 = <0x19>;
			pinctrl-3 = <0x1a>;
			pinctrl-4 = <0x1b>;
			status = "okay";
		};

		uart1@11006000 {
			cell-index = <0x1>;
			compatible = "mediatek,mt8167-uart", "mediatek,mt6577-uart";
			reg = <0x0 0x11006000 0x0 0x1000 0x0 0x11000580 0x0 0x80 0x0 0x11000600 0x0 0x80>;
			interrupts = <0x0 0x55 0x8 0x0 0x62 0x8 0x0 0x63 0x8>;
			clock-frequency = <0x18cba80>;
			clock-div = <0x1>;
			clocks = <0x5 0x4d>;
			clock-names = "uart1-main";
			pinctrl-names = "uart1_gpio_default", "uart1_rx_set", "uart1_rx_clear", "uart1_tx_set", "uart1_tx_clear";
			pinctrl-0 = <0x1c>;
			pinctrl-1 = <0x1d>;
			pinctrl-2 = <0x1e>;
			pinctrl-3 = <0x1f>;
			pinctrl-4 = <0x20>;
			status = "okay";
		};

		uart2@11007000 {
			cell-index = <0x2>;
			compatible = "mediatek,mt8167-uart";
			reg = <0x0 0x11007000 0x0 0x1000 0x0 0x11000980 0x0 0x80 0x0 0x11000a00 0x0 0x80>;
			interrupts = <0x0 0xd4 0x8 0x0 0x64 0x8 0x0 0x65 0x8>;
			clock-frequency = <0x18cba80>;
			clock-div = <0x1>;
			clocks = <0x5 0x79>;
			clock-names = "uart2-main";
			pinctrl-names = "uart2_gpio_default", "uart2_rx_set", "uart2_rx_clear", "uart2_tx_set", "uart2_tx_clear";
			pinctrl-0 = <0x21>;
			pinctrl-1 = <0x22>;
			pinctrl-2 = <0x23>;
			pinctrl-3 = <0x24>;
			pinctrl-4 = <0x25>;
			status = "disable";
		};

		pwm@11008000 {
			compatible = "mediatek,mt8167-pwm";
			reg = <0x0 0x11008000 0x0 0x1000>;
			interrupts = <0x0 0x4c 0x8>;
			clocks = <0x5 0x69 0x5 0x6a 0x5 0x6b 0x5 0x6c 0x5 0x6d 0x5 0x4b 0x5 0x68>;
			clock-names = "PWM1-main", "PWM2-main", "PWM3-main", "PWM4-main", "PWM5-main", "PWM-HCLK-main", "PWM-main";
		};

		i2c@11009000 {
			compatible = "mediatek,mt8167-i2c";
			reg = <0x0 0x11009000 0x0 0x90 0x0 0x11000180 0x0 0x80>;
			interrupts = <0x0 0x50 0x8>;
			clocks = <0x5 0x39 0x4 0x2 0x5 0x45 0x5 0x44>;
			clock-names = "main-source", "main-sel", "main", "dma";
			#address-cells = <0x1>;
			#size-cells = <0x0>;
			status = "okay";
			clock-div = <0x2>;
			pinctrl-names = "default";
			pinctrl-0 = <0x26>;

			lp8557_led@2c {
				compatible = "ti,lp8557-led";
				reg = <0x2c>;
			};

			cap_touch@40 {
				compatible = "mediatek,cap_touch";
				reg = <0x40>;
				interrupt-parent = <0x12>;
				interrupts = <0x64 0x2>;
				int-gpio = <0x12 0x64 0x0>;
				rst-gpio = <0x12 0x65 0x0>;
			};

			strobe_main@63 {
				compatible = "mediatek,strobe_main";
				reg = <0x63>;
			};
		};

		i2c@1100a000 {
			compatible = "mediatek,mt8167-i2c";
			reg = <0x0 0x1100a000 0x0 0x90 0x0 0x11000200 0x0 0x80>;
			interrupts = <0x0 0x51 0x8>;
			clocks = <0x5 0x39 0x4 0x3 0x5 0x46 0x5 0x44>;
			clock-names = "main-source", "main-sel", "main", "dma";
			#address-cells = <0x1>;
			#size-cells = <0x0>;
			status = "okay";
			clock-div = <0x2>;
			pinctrl-names = "default";
			pinctrl-0 = <0x27>;

			gsensor@18 {
				compatible = "mediatek,gsensor1";
				reg = <0x18>;
			};

			nuvoton@1c {
				compatible = "nuvoton,nau8540";
				reg = <0x1c>;
			};

			ad82584f@31 {
				compatible = "ESMT, ad82584f";
				reg = <0x31>;
			};

			sym827@60 {
				compatible = "silergy,sym827-regulator";
				reg = <0x60>;
				regulator-name = "vproc";
				regulator-min-microvolt = <0x927c0>;
				regulator-max-microvolt = <0x152bec>;
				regulator-enable-ramp-delay = <0x190>;
				regulator-ramp-delay = <0x208d>;
				regulator-always-on;
				vsel-gpio = <0x12 0x22 0x0>;
				linux,phandle = <0x57>;
				phandle = <0x57>;
			};
		};

		i2c@1100b000 {
			compatible = "mediatek,mt8167-i2c";
			reg = <0x0 0x1100b000 0x0 0x90 0x0 0x11000280 0x0 0x80>;
			interrupts = <0x0 0x52 0x8>;
			clocks = <0x5 0x39 0x4 0x4 0x5 0x52 0x5 0x44>;
			clock-names = "main-source", "main-sel", "main", "dma";
			#address-cells = <0x1>;
			#size-cells = <0x0>;
			status = "okay";
			clock-div = <0x2>;
			pinctrl-names = "default";
			pinctrl-0 = <0x28>;

			camera_sub_af@18 {
				compatible = "mediatek,camera_sub_af";
				reg = <0x18>;
			};

			kd_camera_hw2@30 {
				compatible = "mediatek,camera_sub";
				reg = <0x30>;
			};

			kd_camera_hw1@36 {
				compatible = "mediatek,camera_main";
				reg = <0x36>;
			};
		};

		spi@1100c000 {
			compatible = "mediatek,mt8167-spi";
			#address-cells = <0x1>;
			#size-cells = <0x0>;
			reg = <0x0 0x1100c000 0x0 0x1000>;
			interrupts = <0x0 0x68 0x8>;
			clocks = <0x5 0x1d 0x5 0xc8 0x5 0x59>;
			clock-names = "parent-clk", "sel-clk", "spi-clk";
			status = "disabled";
		};

		thermal@1100d000 {
			compatible = "mediatek,mt8167-thermal";
			reg = <0x0 0x1100d000 0x0 0x1000>;
			interrupts = <0x0 0x4d 0x8>;
			clocks = <0x5 0x43 0x5 0x5f>;
			clock-names = "therm", "auxadc";
			auxadc = <0x29>;
			apmixedsys = <0x6>;
			infracfg = <0x4>;
		};

		ptp_od@1100d000 {
			compatible = "mediatek,mt8167-ptp_od";
			reg = <0x0 0x1100d000 0x0 0x1000>;
			interrupts = <0x0 0x53 0x8>;
			vproc-supply = <0x8>;
			vcore-supply = <0x2a>;
		};

		btif@1100e000 {
			compatible = "mediatek,btif";
			reg = <0x0 0x1100e000 0x0 0x1000>;
			interrupts = <0x0 0x6b 0x8>;
			clocks = <0x5 0x4e 0x5 0x44>;
			clock-names = "btifc", "apdmac";
		};

		disp_pwm0@1100f000 {
			compatible = "mediatek,mt8167-disp_pwm";
			reg = <0x0 0x1100f000 0x0 0x1000>;
		};

		usb@11100000 {
			compatible = "mediatek,mt8167-usb20";
			reg = <0x0 0x11100000 0x0 0x10000 0x0 0x11110000 0x0 0x10000>;
			interrupts = <0x0 0x48 0x8>;
			mode = <0x2>;
			multipoint = <0x1>;
			dyn_fifo = <0x1>;
			soft_con = <0x1>;
			dma = <0x1>;
			num_eps = <0x10>;
			dma_channels = <0x8>;
			iddig_gpio = <0x12 0x29 0x2>;
			clocks = <0x5 0x28 0x5 0x78 0x5 0x4f 0x5 0x6e>;
			clock-names = "usbpll", "usbmcu", "usb", "icusb";
			pinctrl-names = "iddig_irq_init", "drvvbus_init", "drvvbus_low", "drvvbus_high";
			pinctrl-0 = <0x2b>;
			pinctrl-1 = <0x2c>;
			pinctrl-2 = <0x2d>;
			pinctrl-3 = <0x2e>;
			usb-power-supply = <0x2f>;
			status = "okay";
			drvvbus_gpio = <0x12 0x44 0x0>;
		};

		audio-controller@11140000 {
			compatible = "mediatek,mt8167-afe-pcm";
			reg = <0x0 0x11140000 0x0 0x1000 0x0 0x11141000 0x0 0x9000>;
			interrupts = <0x0 0x78 0x8>;
			clocks = <0x5 0x5b 0x5 0x95 0x5 0x96 0x5 0x97 0x5 0x98 0x5 0x99 0x5 0x9a 0x5 0x9b 0x5 0x9c 0x5 0x9d 0x5 0x8a 0x5 0x86 0x5 0x87 0x5 0x84 0x5 0x85 0x5 0xc0 0x5 0xc1 0x5 0xc2 0x5 0xc3 0x5 0xc4 0x5 0xc5 0x5 0xc6>;
			clock-names = "top_pdn_audio", "apll12_div0", "apll12_div1", "apll12_div2", "apll12_div3", "apll12_div4", "apll12_div4b", "apll12_div5", "apll12_div5b", "apll12_div6", "spdif_in", "engen1", "engen2", "aud1", "aud2", "i2s0_m_sel", "i2s1_m_sel", "i2s2_m_sel", "i2s3_m_sel", "i2s4_m_sel", "i2s5_m_sel", "spdif_b_sel";
			assigned-clocks = <0x5 0xbb 0x5 0xbc 0x5 0xbd 0x5 0xbe>;
			assigned-clock-parents = <0x5 0x29 0x5 0x2d 0x5 0x91 0x5 0x94>;
			mediatek,tdm-out-mode = <0x0>;
			linux,phandle = <0x58>;
			phandle = <0x58>;
		};

		clark@13000000 {
			compatible = "mediatek,mt8167-clark";
			reg = <0x0 0x13000000 0x0 0x80000 0x0 0x13ffe000 0x0 0x1000>;
			interrupts = <0x0 0xb9 0x8>;
			interrupt-names = "RGX";
			power-domains = <0x30 0x5>;
			clocks = <0x5 0xae 0x5 0xb9 0x5 0xba 0x5 0x83 0x5 0x82 0x5 0x3e 0x5 0x31 0x5 0x1e 0x5 0xc 0x5 0xa2>;
			clock-names = "mfg_mm_in_sel", "mfg_axi_in_sel", "mfg_slow_in_sel", "top_slow", "top_axi", "top_mm", "slow_clk26m", "bus_univpll_d24", "bus_mainpll_d11", "engine_csw_mux";
			clock-frequency = <0x17d78400>;
		};

		mfgcfg@13ffe000 {
			compatible = "mediatek,mt8167-mfgcfg", "syscon";
			reg = <0x0 0x13ffe000 0x0 0x1000>;
			#clock-cells = <0x1>;
		};

		mmc@11120000 {
			compatible = "mediatek,mt8167-mmc";
			reg = <0x0 0x11120000 0x0 0x1000>;
			interrupts = <0x0 0x4e 0x8>;
			clocks = <0x5 0x53 0x5 0xa1 0x5 0xd9>;
			clock-names = "source", "hclk", "source_cg";
			status = "okay";
			pinctrl-names = "default", "state_uhs";
			pinctrl-0 = <0x31>;
			pinctrl-1 = <0x32>;
			bus-width = <0x8>;
			max-frequency = <0xbebc200>;
			cap-mmc-highspeed;
			mmc-hs200-1_8v;
			cap-mmc-hw-reset;
			vmmc-supply = <0x33>;
			vqmmc-supply = <0x34>;
			non-removable;
		};

		mmc@11130000 {
			compatible = "mediatek,mt8167-mmc";
			reg = <0x0 0x11130000 0x0 0x1000>;
			interrupts = <0x0 0x4f 0x8>;
			clocks = <0x5 0x54 0x5 0xa1 0x5 0xda>;
			clock-names = "source", "hclk", "source_cg";
			status = "disabled";
		};

		audiotop@11140000 {
			compatible = "mediatek,mt8167-audiotop", "syscon";
			reg = <0x0 0x11140000 0x0 0x1000>;
			#clock-cells = <0x1>;
		};

		sdio@11170000 {
			compatible = "mediatek,mt8167-sdio";
			reg = <0x0 0x11170000 0x0 0x1000>;
			interrupts = <0x0 0x6d 0x8>;
			clocks = <0x5 0x61 0x5 0xdb>;
			clock-names = "sdio-bus", "sdio-src";
			status = "disabled";
		};

		usb@11190000 {
			compatible = "mediatek,mt8167-usb11";
			cell-index = <0x1>;
			reg = <0x0 0x11190000 0x0 0x10000 0x0 0x11110000 0x0 0x10000>;
			interrupts = <0x0 0xd2 0x8>;
			mode = <0x2>;
			multipoint = <0x1>;
			dyn_fifo = <0x1>;
			soft_con = <0x1>;
			dma = <0x1>;
			num_eps = <0x8>;
			dma_channels = <0x4>;
		};

		mmsys@14000000 {
			compatible = "mediatek,mt8167-mmsys", "syscon";
			reg = <0x0 0x14000000 0x0 0x1000>;
			#clock-cells = <0x1>;
			linux,phandle = <0x16>;
			phandle = <0x16>;
		};

		mdp_rdma@14001000 {
			compatible = "mediatek,mt8167-mdp_rdma";
			reg = <0x0 0x14001000 0x0 0x1000>;
			interrupts = <0x0 0x9a 0x8>;
		};

		mdp_rsz0@14002000 {
			compatible = "mediatek,mt8167-mdp_rsz0";
			reg = <0x0 0x14002000 0x0 0x1000>;
			interrupts = <0x0 0x9b 0x8>;
		};

		mdp_rsz1@14003000 {
			compatible = "mediatek,mt8167-mdp_rsz1";
			reg = <0x0 0x14003000 0x0 0x1000>;
			interrupts = <0x0 0x9c 0x8>;
		};

		mdp_wdma@14004000 {
			compatible = "mediatek,mt8167-mdp_wdma";
			reg = <0x0 0x14004000 0x0 0x1000>;
			interrupts = <0x0 0x9e 0x8>;
		};

		mdp_wrot@14005000 {
			compatible = "mediatek,mt8167-mdp_wrot";
			reg = <0x0 0x14005000 0x0 0x1000>;
			interrupts = <0x0 0x9f 0x8>;
		};

		mdp_tdshp@14006000 {
			compatible = "mediatek,mdp_tdshp";
			reg = <0x0 0x14006000 0x0 0x1000>;
			interrupts = <0x0 0x9d 0x8>;
		};

		mt8167-dispsys {
			compatible = "mediatek,mt8167-dispsys";
			mediatek,larb = <0x13>;
			clocks = <0x16 0x9 0x16 0xa 0x16 0xb 0x16 0xc 0x16 0xd 0x16 0xe 0x16 0xf 0x16 0x10 0x16 0x11 0x16 0x12 0x16 0x13 0x5 0x3c 0x16 0x14 0x16 0x15 0x16 0x16 0x16 0x17 0x16 0x19 0x16 0x18 0x16 0x1a 0x16 0x1b 0x16 0x1d 0x16 0x1c 0x5 0x33 0x5 0x40 0x5 0x80 0x5 0xb7 0x6 0x7 0x5 0x25 0x5 0x26 0x5 0x27 0x5 0x81 0x5 0xb8 0x6 0x6 0x5 0x35 0x5 0x36 0x5 0x37 0x5 0x38 0x5 0xc7 0x5 0x1d>;
			clock-names = "MMSYS_CLK_FAKE_ENG", "MMSYS_CLK_DISP_OVL0", "MMSYS_CLK_DISP_RDMA0", "MMSYS_CLK_DISP_RDMA1", "MMSYS_CLK_DISP_WDMA0", "MMSYS_CLK_DISP_COLOR", "MMSYS_CLK_DISP_CCORR", "MMSYS_CLK_DISP_AAL", "MMSYS_CLK_DISP_GAMMA", "MMSYS_CLK_DISP_DITHER", "MMSYS_CLK_DISP_UFOE", "MMSYS_CLK_TOP_PWM_MM", "MMSYS_CLK_DISP_PWM", "MMSYS_CLK_DISP_PWM26M", "MMSYS_CLK_DSI_ENGINE", "MMSYS_CLK_DSI_DIGITAL", "MMSYS_CLK_DPI0_PIXEL", "MMSYS_CLK_DPI0_ENGINE", "MMSYS_CLK_LVDS_PIXEL", "MMSYS_CLK_LVDS_CTS", "MMSYS_CLK_DPI1_PIXEL", "MMSYS_CLK_DPI1_ENGINE", "MMSYS_CLK_TOP_MIPI_26M", "MMSYS_CLK_TOP_MIPI_26M_DBG", "MMSYS_CLK_TOP_RG_FDPI0", "MMSYS_CLK_MUX_DPI0_SEL", "MMSYS_APMIXED_LVDSPLL", "MMSYS_CLK_MUX_LVDSPLL_D2", "MMSYS_CLK_MUX_LVDSPLL_D4", "MMSYS_CLK_MUX_LVDSPLL_D8", "MMSYS_CLK_TOP_RG_FDPI1", "MMSYS_CLK_MUX_DPI1_SEL", "MMSYS_APMIXED_TVDPLL", "MMSYS_CLK_MUX_TVDPLL_D2", "MMSYS_CLK_MUX_TVDPLL_D4", "MMSYS_CLK_MUX_TVDPLL_D8", "MMSYS_CLK_MUX_TVDPLL_D16", "MMSYS_CLK_PWM_SEL", "TOP_UNIVPLL_D12";
		};

		disp_ovl0@14007000 {
			compatible = "mediatek,mt8167-disp_ovl0";
			reg = <0x0 0x14007000 0x0 0x1000>;
			interrupts = <0x0 0xa0 0x8>;
		};

		disp_rdma0@14009000 {
			compatible = "mediatek,mt8167-disp_rdma0";
			reg = <0x0 0x14009000 0x0 0x1000>;
			interrupts = <0x0 0xa2 0x8>;
		};

		disp_rdma1@1400a000 {
			compatible = "mediatek,mt8167-disp_rdma1";
			reg = <0x0 0x1400a000 0x0 0x1000>;
			interrupts = <0x0 0xa3 0x8>;
		};

		disp_wdma0@1400b000 {
			compatible = "mediatek,mt8167-disp_wdma0";
			reg = <0x0 0x1400b000 0x0 0x1000>;
			interrupts = <0x0 0xa4 0x8>;
		};

		disp_color@1400c000 {
			compatible = "mediatek,mt8167-disp_color";
			reg = <0x0 0x1400c000 0x0 0x1000>;
			interrupts = <0x0 0xa5 0x8>;
		};

		disp_ccorr@1400d000 {
			compatible = "mediatek,mt8167-disp_ccorr";
			reg = <0x0 0x1400d000 0x0 0x1000>;
			interrupts = <0x0 0xa6 0x8>;
		};

		disp_aal@1400e000 {
			compatible = "mediatek,mt8167-disp_aal";
			reg = <0x0 0x1400e000 0x0 0x1000>;
			interrupts = <0x0 0xa7 0x8>;
		};

		disp_gamma@1400f000 {
			compatible = "mediatek,mt8167-disp_gamma";
			reg = <0x0 0x1400f000 0x0 0x1000>;
			interrupts = <0x0 0xa8 0x8>;
		};

		disp_dither@14010000 {
			compatible = "mediatek,mt8167-disp_dither";
			reg = <0x0 0x14010000 0x0 0x1000>;
			interrupts = <0x0 0xa9 0x8>;
		};

		disp_dsi0@14012000 {
			compatible = "mediatek,mt8167-disp_dsi0";
			reg = <0x0 0x14012000 0x0 0x1000>;
			interrupts = <0x0 0xab 0x8>;
		};

		disp_dpi0@14013000 {
			compatible = "mediatek,mt8167-disp_dpi0";
			reg = <0x0 0x14013000 0x0 0x1000>;
			interrupts = <0x0 0xac 0x8>;
		};

		mm_mutex@14015000 {
			compatible = "mediatek,mt8167-disp_mutex";
			reg = <0x0 0x14015000 0x0 0x1000>;
			interrupts = <0x0 0x99 0x8>;
		};

		mipi_dphy@14018000 {
			compatible = "mediatek,mt8167-disp_mipi_tx";
			reg = <0x0 0x14018000 0x0 0x90>;
		};

		disp_lvds_ana@14018800 {
			compatible = "mediatek,mt8167-disp_lvds_ana";
			reg = <0x0 0x14018800 0x0 0x1c>;
		};

		disp_dpi1@14019000 {
			compatible = "mediatek,mt8167-disp_dpi1";
			reg = <0x0 0x14019000 0x0 0x1000>;
			interrupts = <0x0 0xae 0x8>;
		};

		disp_lvds_tx@1401a200 {
			compatible = "mediatek,mt8167-disp_lvds_tx";
			reg = <0x0 0x1401a200 0x0 0x64>;
		};

		hdmi@1401b000 {
			compatible = "mediatek,mt8167-hdmitx";
			power-domains = <0x30 0x0>;
			reg = <0x0 0x1401b000 0x0 0x1000 0x0 0x11011000 0x0 0x10 0x0 0x1001a000 0x0 0xbc>;
			interrupts = <0x0 0x94 0x8>;
			clocks = <0x5 0x70 0x5 0x71 0x5 0x72 0x16 0x1e 0x16 0x21 0x16 0x20 0x16 0x1f>;
			clock-names = "clk_ddc", "clk_cec_26m", "clk_cec_32k", "mmsys_hdmi_pixel", "mmsys_hdmi_pll", "mmsys_hdmi_audio", "mmsys_hdmi_spidif";
			status = "okay";
			pinctrl-names = "default", "hdmi_hpd";
			pinctrl-0 = <0x35>;
			pinctrl-1 = <0x36>;
		};

		g3d_iommu@13005000 {
			cell-index = <0x2>;
			compatible = "mediatek,mt8167-g3d_iommu";
			reg = <0x0 0x13005000 0x0 0x1000>;
			interrupts = <0x0 0xe2 0x8>;
		};

		larb@14016000 {
			compatible = "mediatek,mt8167-smi-larb";
			reg = <0x0 0x14016000 0x0 0x1000>;
			mediatek,smi = <0x37>;
			mediatek,larbid = <0x0>;
			clocks = <0x16 0x1 0x16 0x1>;
			clock-names = "apb", "smi";
			power-domains = <0x30 0x0>;
			linux,phandle = <0x13>;
			phandle = <0x13>;
		};

		smi@14017000 {
			compatible = "mediatek,mt8167-smi-common";
			reg = <0x0 0x14017000 0x0 0x1000>;
			clocks = <0x16 0x0 0x16 0x0>;
			clock-names = "apb", "smi";
			power-domains = <0x30 0x0>;
			linux,phandle = <0x37>;
			phandle = <0x37>;
		};

		met_smi@14017000 {
			compatible = "mediatek,met_smi";
			reg = <0x0 0x14017000 0x0 0x1000 0x0 0x14016000 0x0 0x1000 0x0 0x15001000 0x0 0x1000 0x0 0x16010000 0x0 0x1000>;
			clocks = <0x16 0x0 0x16 0x1 0x38 0x0 0x39 0x0>;
			clock-names = "smi-common", "smi-larb0", "img-larb1", "vdec-larb2";
		};

		imgsys@15000000 {
			compatible = "mediatek,mt8167-imgsys", "syscon";
			reg = <0x0 0x15000000 0x0 0x1000>;
			#clock-cells = <0x1>;
			linux,phandle = <0x38>;
			phandle = <0x38>;
		};

		isp_display {
			compatible = "mediatek,mt8167-isp_display";
		};

		ispsys@15000000 {
			compatible = "mediatek,mt8167-ispsys";
			reg = <0x0 0x15004000 0x0 0x9000 0x0 0x15000000 0x0 0x10000 0x0 0x10011000 0x0 0x3000>;
			interrupts = <0x0 0xb4 0x8 0x0 0xb7 0x8>;
			clocks = <0x38 0x0 0x38 0x1 0x38 0x2 0x38 0x3 0x38 0x4 0x16 0x0>;
			clock-names = "IMG_LARB_SMI", "IMG_CAM_SMI", "IMG_CAM_CAM", "IMG_SEN_TG", "IMG_SEN_CAM", "MM_SMI_COMMON";
			mediatek,smilarb = <0x14>;
		};

		vencsys@15000000 {
			status = "disabled";
			compatible = "mediatek,mt8167-vencsys", "syscon";
			reg = <0x0 0x15000000 0x0 0x1000>;
			#clock-cells = <0x1>;
		};

		larb@15001000 {
			compatible = "mediatek,mt8167-smi-larb";
			reg = <0x0 0x15001000 0x0 0x10000>;
			mediatek,smi = <0x37>;
			mediatek,larbid = <0x1>;
			clocks = <0x38 0x0 0x38 0x0>;
			clock-names = "apb", "smi";
			power-domains = <0x30 0x2>;
			linux,phandle = <0x14>;
			phandle = <0x14>;
		};

		camera1@15008000 {
			compatible = "mediatek,mt8167-camera_hw";
			reg = <0x0 0x15008000 0x0 0x1000>;
			clocks = <0x5 0xa4 0x5 0x40 0x5 0x3d 0x5 0x28 0x5 0x1c>;
			clock-names = "TOP_CAMTG_SEL", "TOP_CAM_MIPI_26M", "TOP_CAMTG", "TOP_CAM_TG_48M", "TOP_CAM_TG_208M";
			reg-vcama-supply = <0x3a>;
			reg-vcamd-supply = <0x3b>;
			reg-vcamio-supply = <0x3c>;
			reg-vcamaf-supply = <0x3d>;
			pinctrl-names = "default", "cam0_rst0", "cam0_rst1", "cam0_pnd0", "cam0_pnd1", "cam1_rst0", "cam1_rst1", "cam1_pnd0", "cam1_pnd1", "cam_ldo0_0", "cam_ldo0_1";
			pinctrl-0 = <0x3e>;
			pinctrl-1 = <0x3f>;
			pinctrl-2 = <0x40>;
			pinctrl-3 = <0x41>;
			pinctrl-4 = <0x42>;
			pinctrl-5 = <0x43>;
			pinctrl-6 = <0x44>;
			pinctrl-7 = <0x45>;
			pinctrl-8 = <0x46>;
			status = "okay";
		};

		camera2@15008000 {
			compatible = "mediatek,mt8167-camera_hw2";
			reg = <0x0 0x15008000 0x0 0x1000>;
			reg-vcama-supply = <0x3a>;
			reg-vcamd-supply = <0x3b>;
			reg-vcamio-supply = <0x3c>;
			reg-vcamaf-supply = <0x3d>;
		};

		venc@15009000 {
			compatible = "mediatek,mt8167-venc";
			reg = <0x0 0x15009000 0x0 0x1000>;
			interrupts = <0x0 0xb3 0x8>;
			clocks = <0x38 0x5>;
			clock-names = "img_venc";
		};

		vdecsys@16000000 {
			compatible = "mediatek,mt8167-vdecsys", "syscon";
			reg = <0x0 0x16000000 0x0 0x1000>;
			#clock-cells = <0x1>;
			linux,phandle = <0x39>;
			phandle = <0x39>;
		};

		vdec_gcon@16000000 {
			compatible = "mediatek,mt8167-vdec_gcon";
			reg = <0x0 0x16000000 0x0 0x10000>;
			clocks = <0x39 0x0 0x39 0x1>;
			clock-names = "apb", "smi";
		};

		larb@16010000 {
			compatible = "mediatek,mt8167-smi-larb";
			reg = <0x0 0x16010000 0x0 0x1000>;
			mediatek,smi = <0x37>;
			mediatek,larbid = <0x2>;
			clocks = <0x39 0x0 0x39 0x1>;
			clock-names = "apb", "smi";
			power-domains = <0x30 0x1>;
			linux,phandle = <0x15>;
			phandle = <0x15>;
		};

		vdec@16020000 {
			compatible = "mediatek,mt8167-vdec";
			reg = <0x0 0x16020000 0x0 0x10000>;
			clocks = <0x5 0xb6 0x5 0x18>;
			clock-names = "vdec_sel", "normal";
			interrupts = <0x0 0xb8 0x8>;
		};

		consys@18070000 {
			compatible = "mediatek,mt8167-consys";
			reg = <0x0 0x18070000 0x0 0x200 0x0 0x10000000 0x0 0x2000>;
			power-domains = <0x30 0x6>;
			interrupts = <0x0 0xc3 0x8 0x0 0xc5 0x8>;
			resets = <0x47 0xc>;
			reset-names = "connsys";
			status = "okay";
			pinctrl-names = "default", "gps_lna_state_init", "gps_lna_state_oh", "gps_lna_state_ol";
			pinctrl-0 = <0x48>;
			pinctrl-1 = <0x49>;
			pinctrl-2 = <0x4a>;
			pinctrl-3 = <0x4b>;
			vcn18-supply = <0x4c>;
			vcn35-supply = <0x4d>;
		};

		wifi@180f0000 {
			compatible = "mediatek,wifi";
			reg = <0x0 0x180f0000 0x0 0x5c>;
			interrupts = <0x0 0xc4 0x8>;
			clocks = <0x5 0x44>;
			clock-names = "wifi-dma";
		};

		touch@ {
			compatible = "mediatek,mt8167-touch", "mediatek,mt8163-touch";
			vtouch-supply = <0x4e>;
			tpd-resolution = <0x258 0x400>;
			use-tpd-button = <0x0>;
			tpd-key-num = <0x4>;
			tpd-key-local = <0x8b 0xac 0x9e 0x0>;
			tpd-key-dim-local = <0x3c 0x352 0x32 0x1e 0xb4 0x352 0x32 0x1e 0x12c 0x352 0x32 0x1e 0x1a4 0x352 0x32 0x1e>;
			tpd-max-touch-num = <0x5>;
			tpd-filter-enable = <0x1>;
			tpd-filter-pixel-density = <0x7c>;
			tpd-filter-custom-prameters = <0x0 0x0 0x0 0x0 0x0 0x0 0x0 0x0 0x0 0x0 0x0 0x0>;
			tpd-filter-custom-speed = <0x0 0x0 0x0>;
			pinctrl-names = "default", "state_eint_as_int", "state_eint_output0", "state_eint_output1", "state_rst_output0", "state_rst_output1";
			pinctrl-0 = <0x4f>;
			pinctrl-1 = <0x50>;
			pinctrl-2 = <0x51>;
			pinctrl-3 = <0x52>;
			pinctrl-4 = <0x53>;
			pinctrl-5 = <0x54>;
			status = "okay";
		};

		gps {
			compatible = "mediatek,gps";
		};

		hwmsensor@0 {
			compatible = "mediatek,hwmsensor";
		};

		gsensor@0 {
			compatible = "mediatek,gsensor";
		};

		als_ps@0 {
			compatible = "mediatek,als_ps";
		};

		batchsensor@0 {
			compatible = "mediatek,batchsensor";
		};

		gyroscope@0 {
			compatible = "mediatek,gyroscope";
		};

		barometer@0 {
			compatible = "mediatek,barometer";
		};

		msensor@0 {
			compatible = "mediatek,msensor";
		};

		orientation@0 {
			compatible = "mediatek,orientation";
		};

		led@0 {
			compatible = "mediatek,red";
			led_mode = <0x6>;
			data = <0x0>;
			pwm_config = <0x0 0x0 0x0 0x0 0x0>;
		};

		led@1 {
			compatible = "mediatek,green";
			led_mode = <0x6>;
			data = <0x1>;
			pwm_config = <0x0 0x0 0x0 0x0 0x0>;
		};

		led@2 {
			compatible = "mediatek,blue";
			led_mode = <0x6>;
			data = <0x2>;
			pwm_config = <0x0 0x0 0x0 0x0 0x0>;
		};

		led@3 {
			compatible = "mediatek,jogball-backlight";
			led_mode = <0x0>;
			data;
			pwm_config = <0x0 0x0 0x0 0x0 0x0>;
		};

		led@4 {
			compatible = "mediatek,keyboard-backlight";
			led_mode = <0x0>;
			data;
			pwm_config = <0x0 0x0 0x0 0x0 0x0>;
		};

		led@5 {
			compatible = "mediatek,button-backlight";
			led_mode = <0x0>;
			data;
			pwm_config = <0x0 0x0 0x0 0x0 0x0>;
		};

		led@6 {
			compatible = "mediatek,lcd-backlight";
			led_mode = <0x5>;
			data;
			pwm_config = <0x0 0x0 0x0 0x0 0x0>;
		};

		mtkfb@0 {
			compatible = "mediatek,MTKFB";
			mediatek,larb = <0x13>;
		};

		bat_meter {
			compatible = "mediatek,bat_meter";
			r_bat_sense = <0x4>;
			r_i_sense = <0x4>;
			r_charger_1 = <0x14a>;
			r_charger_2 = <0x27>;
			temperature_t0 = <0x6e>;
			temperature_t1 = <0x0>;
			temperature_t2 = <0x19>;
			temperature_t3 = <0x32>;
			temperature_t = <0xff>;
			fg_meter_resistance = <0x0>;
			q_max_pos_50 = <0x779>;
			q_max_pos_25 = <0x76c>;
			q_max_pos_0 = <0x6ed>;
			q_max_neg_10 = <0x699>;
			q_max_pos_50_h_current = <0x75a>;
			q_max_pos_25_h_current = <0x736>;
			q_max_pos_0_h_current = <0x641>;
			q_max_neg_10_h_current = <0x366>;
			oam_d5 = <0x0>;
			change_tracking_point = <0x1>;
			cust_tracking_point = <0xe>;
			cust_r_sense = <0xc8>;
			cust_hw_cc = <0x0>;
			aging_tuning_value = <0x64>;
			cust_r_fg_offset = <0x0>;
			ocv_board_compesate = <0x0>;
			r_fg_board_base = <0x3e8>;
			r_fg_board_slope = <0x3e8>;
			car_tune_value = <0x59>;
			current_detect_r_fg = <0xa>;
			minerroroffset = <0x3e8>;
			fg_vbat_average_size = <0x12>;
			r_fg_value = <0xa>;
			cust_poweron_delta_capacity_tolrance = <0x50>;
			cust_poweron_low_capacity_tolrance = <0x2>;
			cust_poweron_max_vbat_tolrance = <0x46>;
			cust_poweron_delta_vbat_tolrance = <0x3c>;
			cust_poweron_delta_hw_sw_ocv_capacity_tolrance = <0xa>;
			fixed_tbat_25 = <0x1>;
			vbat_normal_wakeup = <0xe10>;
			vbat_low_power_wakeup = <0xdac>;
			normal_wakeup_period = <0x1518>;
			low_power_wakeup_period = <0x12c>;
			close_poweroff_wakeup_period = <0x1e>;
			rbat_pull_up_r = <0x4204>;
			rbat_pull_up_volt = <0x708>;
			batt_temperature_table_num = <0x11>;
			batt_temperature_table = <0xffffffec 0x129d1 0xfffffff1 0xe519 0xfffffff6 0xb201 0xfffffffb 0x8b97 0x0 0x6e6f 0x5 0x5817 0xa 0x46d8 0xf 0x3968 0x14 0x2edd 0x19 0x2710 0x1e 0x20ad 0x23 0x1b63 0x28 0x173f 0x2d 0x1380 0x32 0x1079 0x37 0xdfb 0x3c 0xbeb>;
			battery_profile_t0_num = <0x39>;
			battery_profile_t0 = <0x0 0x104f 0x2 0x1038 0x4 0x1025 0x5 0x1013 0x7 0x1002 0x9 0xff3 0xb 0xfe5 0xd 0xfd6 0xe 0xfc5 0x10 0xfb4 0x12 0xfa5 0x14 0xf99 0x15 0xf8d 0x17 0xf83 0x19 0xf77 0x1b 0xf6c 0x1d 0xf61 0x1e 0xf57 0x20 0xf4d 0x22 0xf43 0x24 0xf39 0x26 0xf2e 0x27 0xf23 0x29 0xf15 0x2b 0xf08 0x2d 0xefc 0x2f 0xef2 0x30 0xeea 0x32 0xee3 0x34 0xedd 0x36 0xed8 0x37 0xed3 0x39 0xecf 0x3b 0xecc 0x3d 0xec7 0x3f 0xec4 0x40 0xec1 0x42 0xebf 0x44 0xebd 0x46 0xebb 0x48 0xeb9 0x49 0xeb6 0x4b 0xeb2 0x4d 0xeab 0x4f 0xea4 0x50 0xe9d 0x52 0xe95 0x54 0xe89 0x56 0xe7e 0x58 0xe6e 0x59 0xe69 0x5b 0xe66 0x5d 0xe64 0x5f 0xe5f 0x61 0xe36 0x62 0xdd8 0x64 0xd35>;
			battery_profile_t1_num = <0x39>;
			battery_profile_t1 = <0x0 0x104f 0x2 0x1038 0x4 0x1025 0x5 0x1013 0x7 0x1002 0x9 0xff3 0xb 0xfe5 0xd 0xfd6 0xe 0xfc5 0x10 0xfb4 0x12 0xfa5 0x14 0xf99 0x15 0xf8d 0x17 0xf83 0x19 0xf77 0x1b 0xf6c 0x1d 0xf61 0x1e 0xf57 0x20 0xf4d 0x22 0xf43 0x24 0xf39 0x26 0xf2e 0x27 0xf23 0x29 0xf15 0x2b 0xf08 0x2d 0xefc 0x2f 0xef2 0x30 0xeea 0x32 0xee3 0x34 0xedd 0x36 0xed8 0x37 0xed3 0x39 0xecf 0x3b 0xecc 0x3d 0xec7 0x3f 0xec4 0x40 0xec1 0x42 0xebf 0x44 0xebd 0x46 0xebb 0x48 0xeb9 0x49 0xeb6 0x4b 0xeb2 0x4d 0xeab 0x4f 0xea4 0x50 0xe9d 0x52 0xe95 0x54 0xe89 0x56 0xe7e 0x58 0xe6e 0x59 0xe69 0x5b 0xe66 0x5d 0xe64 0x5f 0xe5f 0x61 0xe36 0x62 0xdd8 0x64 0xd35>;
			battery_profile_t2_num = <0x39>;
			battery_profile_t2 = <0x0 0x104f 0x2 0x1038 0x4 0x1025 0x5 0x1013 0x7 0x1002 0x9 0xff3 0xb 0xfe5 0xd 0xfd6 0xe 0xfc5 0x10 0xfb4 0x12 0xfa5 0x14 0xf99 0x15 0xf8d 0x17 0xf83 0x19 0xf77 0x1b 0xf6c 0x1d 0xf61 0x1e 0xf57 0x20 0xf4d 0x22 0xf43 0x24 0xf39 0x26 0xf2e 0x27 0xf23 0x29 0xf15 0x2b 0xf08 0x2d 0xefc 0x2f 0xef2 0x30 0xeea 0x32 0xee3 0x34 0xedd 0x36 0xed8 0x37 0xed3 0x39 0xecf 0x3b 0xecc 0x3d 0xec7 0x3f 0xec4 0x40 0xec1 0x42 0xebf 0x44 0xebd 0x46 0xebb 0x48 0xeb9 0x49 0xeb6 0x4b 0xeb2 0x4d 0xeab 0x4f 0xea4 0x50 0xe9d 0x52 0xe95 0x54 0xe89 0x56 0xe7e 0x58 0xe6e 0x59 0xe69 0x5b 0xe66 0x5d 0xe64 0x5f 0xe5f 0x61 0xe36 0x62 0xdd8 0x64 0xd35>;
			battery_profile_t3_num = <0x39>;
			battery_profile_t3 = <0x0 0x104f 0x2 0x1038 0x4 0x1025 0x5 0x1013 0x7 0x1002 0x9 0xff3 0xb 0xfe5 0xd 0xfd6 0xe 0xfc5 0x10 0xfb4 0x12 0xfa5 0x14 0xf99 0x15 0xf8d 0x17 0xf83 0x19 0xf77 0x1b 0xf6c 0x1d 0xf61 0x1e 0xf57 0x20 0xf4d 0x22 0xf43 0x24 0xf39 0x26 0xf2e 0x27 0xf23 0x29 0xf15 0x2b 0xf08 0x2d 0xefc 0x2f 0xef2 0x30 0xeea 0x32 0xee3 0x34 0xedd 0x36 0xed8 0x37 0xed3 0x39 0xecf 0x3b 0xecc 0x3d 0xec7 0x3f 0xec4 0x40 0xec1 0x42 0xebf 0x44 0xebd 0x46 0xebb 0x48 0xeb9 0x49 0xeb6 0x4b 0xeb2 0x4d 0xeab 0x4f 0xea4 0x50 0xe9d 0x52 0xe95 0x54 0xe89 0x56 0xe7e 0x58 0xe6e 0x59 0xe69 0x5b 0xe66 0x5d 0xe64 0x5f 0xe5f 0x61 0xe36 0x62 0xdd8 0x64 0xd35>;
			r_profile_t0_num = <0x39>;
			r_profile_t0 = <0x91 0x104f 0x91 0x1038 0x93 0x1025 0x93 0x1013 0x94 0x1002 0x96 0xff3 0x99 0xfe5 0x9b 0xfd6 0x9d 0xfc5 0x9d 0xfb4 0xa0 0xfa5 0xa5 0xf99 0xa5 0xf8d 0xa8 0xf83 0xaa 0xf77 0xac 0xf6c 0xad 0xf61 0xb1 0xf57 0xb1 0xf4d 0xb2 0xf43 0xb2 0xf39 0xb1 0xf2e 0xaf 0xf23 0xa7 0xf15 0xa0 0xf08 0x99 0xefc 0x96 0xef2 0x96 0xeea 0x94 0xee3 0x94 0xedd 0x94 0xed8 0x96 0xed3 0x98 0xecf 0x99 0xecc 0x98 0xec7 0x99 0xec4 0x9b 0xec1 0x9d 0xebf 0x9d 0xebd 0x9d 0xebb 0x9d 0xeb9 0x9d 0xeb6 0x9b 0xeb2 0x98 0xeab 0x96 0xea4 0x94 0xe9d 0x98 0xe95 0x94 0xe89 0x98 0xe7e 0x93 0xe6e 0x93 0xe69 0x94 0xe66 0x9e 0xe64 0xaa 0xe5f 0xa2 0xe36 0xa5 0xdd8 0xbe 0xd35>;
			r_profile_t1_num = <0x39>;
			r_profile_t1 = <0x91 0x104f 0x91 0x1038 0x93 0x1025 0x93 0x1013 0x94 0x1002 0x96 0xff3 0x99 0xfe5 0x9b 0xfd6 0x9d 0xfc5 0x9d 0xfb4 0xa0 0xfa5 0xa5 0xf99 0xa5 0xf8d 0xa8 0xf83 0xaa 0xf77 0xac 0xf6c 0xad 0xf61 0xb1 0xf57 0xb1 0xf4d 0xb2 0xf43 0xb2 0xf39 0xb1 0xf2e 0xaf 0xf23 0xa7 0xf15 0xa0 0xf08 0x99 0xefc 0x96 0xef2 0x96 0xeea 0x94 0xee3 0x94 0xedd 0x94 0xed8 0x96 0xed3 0x98 0xecf 0x99 0xecc 0x98 0xec7 0x99 0xec4 0x9b 0xec1 0x9d 0xebf 0x9d 0xebd 0x9d 0xebb 0x9d 0xeb9 0x9d 0xeb6 0x9b 0xeb2 0x98 0xeab 0x96 0xea4 0x94 0xe9d 0x98 0xe95 0x94 0xe89 0x98 0xe7e 0x93 0xe6e 0x93 0xe69 0x94 0xe66 0x9e 0xe64 0xaa 0xe5f 0xa2 0xe36 0xa5 0xdd8 0xbe 0xd35>;
			r_profile_t2_num = <0x39>;
			r_profile_t2 = <0x91 0x104f 0x91 0x1038 0x93 0x1025 0x93 0x1013 0x94 0x1002 0x96 0xff3 0x99 0xfe5 0x9b 0xfd6 0x9d 0xfc5 0x9d 0xfb4 0xa0 0xfa5 0xa5 0xf99 0xa5 0xf8d 0xa8 0xf83 0xaa 0xf77 0xac 0xf6c 0xad 0xf61 0xb1 0xf57 0xb1 0xf4d 0xb2 0xf43 0xb2 0xf39 0xb1 0xf2e 0xaf 0xf23 0xa7 0xf15 0xa0 0xf08 0x99 0xefc 0x96 0xef2 0x96 0xeea 0x94 0xee3 0x94 0xedd 0x94 0xed8 0x96 0xed3 0x98 0xecf 0x99 0xecc 0x98 0xec7 0x99 0xec4 0x9b 0xec1 0x9d 0xebf 0x9d 0xebd 0x9d 0xebb 0x9d 0xeb9 0x9d 0xeb6 0x9b 0xeb2 0x98 0xeab 0x96 0xea4 0x94 0xe9d 0x98 0xe95 0x94 0xe89 0x98 0xe7e 0x93 0xe6e 0x93 0xe69 0x94 0xe66 0x9e 0xe64 0xaa 0xe5f 0xa2 0xe36 0xa5 0xdd8 0xbe 0xd35>;
			r_profile_t3_num = <0x39>;
			r_profile_t3 = <0x91 0x104f 0x91 0x1038 0x93 0x1025 0x93 0x1013 0x94 0x1002 0x96 0xff3 0x99 0xfe5 0x9b 0xfd6 0x9d 0xfc5 0x9d 0xfb4 0xa0 0xfa5 0xa5 0xf99 0xa5 0xf8d 0xa8 0xf83 0xaa 0xf77 0xac 0xf6c 0xad 0xf61 0xb1 0xf57 0xb1 0xf4d 0xb2 0xf43 0xb2 0xf39 0xb1 0xf2e 0xaf 0xf23 0xa7 0xf15 0xa0 0xf08 0x99 0xefc 0x96 0xef2 0x96 0xeea 0x94 0xee3 0x94 0xedd 0x94 0xed8 0x96 0xed3 0x98 0xecf 0x99 0xecc 0x98 0xec7 0x99 0xec4 0x9b 0xec1 0x9d 0xebf 0x9d 0xebd 0x9d 0xebb 0x9d 0xeb9 0x9d 0xeb6 0x9b 0xeb2 0x98 0xeab 0x96 0xea4 0x94 0xe9d 0x98 0xe95 0x94 0xe89 0x98 0xe7e 0x93 0xe6e 0x93 0xe69 0x94 0xe66 0x9e 0xe64 0xaa 0xe5f 0xa2 0xe36 0xa5 0xdd8 0xbe 0xd35>;
		};

		BAT_NOTIFY {
			compatible = "mediatek,bat_notify";
		};

		bat_comm {
			compatible = "mediatek,battery";
			stop_charging_in_takling = <0x1>;
			talking_recharge_voltage = <0xed8>;
			talking_sync_time = <0x3c>;
			mtk_temperature_recharge_support = <0x1>;
			max_charge_temperature = <0x32>;
			max_charge_temperature_minus_x_degree = <0x2f>;
			min_charge_temperature = <0x0>;
			min_charge_temperature_plus_x_degree = <0x6>;
			err_charge_temperature = <0xff>;
			v_pre2cc_thres = <0xd48>;
			v_cc2topoff_thres = <0xfd2>;
			recharging_voltage = <0x100e>;
			charging_full_current = <0x64>;
			config_usb_if = <0x0>;
			usb_charger_current_suspend = <0x0>;
			usb_charger_current_unconfigured = <0x1b58>;
			usb_charger_current_configured = <0xc350>;
			usb_charger_current = <0xc350>;
			ac_charger_current = <0x186a0>;
			non_std_ac_charger_current = <0xc350>;
			charging_host_charger_current = <0xfde8>;
			apple_0_5a_charger_current = <0xc350>;
			apple_1_0a_charger_current = <0xfde8>;
			apple_2_1a_charger_current = <0x13880>;
			bat_low_temp_protect_enable = <0x0>;
			v_charger_enable = <0x0>;
			v_charger_max = <0x1964>;
			v_charger_min = <0x1130>;
			onehundred_percent_tracking_time = <0xa>;
			npercent_tracking_time = <0x14>;
			sync_to_real_tracking_time = <0x3c>;
			v_0percent_tracking = <0xd7a>;
			high_battery_voltage_support = <0x0>;
			interrupt-parent = <0x55>;
			interrupts = <0xa 0x4>;
		};

		dumchar {
			compatible = "mediatek,mt8167-dummy_char";
		};

		extd_drv@0 {
			compatible = "mediatek,extd_dev";
		};

		led_en {
			compatible = "emdoor,ts809_led_en";
		};

		flashlight_core {
			compatible = "mediatek,flashlight_core";
		};

		flashlights_lm3642 {
			compatible = "mediatek,flashlights_lm3642";
		};

		ice_debug {
			compatible = "mediatek,mt8167-ice_debug", "mediatek,mt8173-ice_debug";
			clocks = <0x5 0x4a>;
			clock-names = "ice_dbg";
		};

		isp_pipemgr {
			compatible = "mediatek,mt8167-isp_pipemgr";
		};

		isp_sysram {
			compatible = "mediatek,mt8167-isp_sysram";
		};

		mfgsys-async {
			compatible = "mediatek,mt8167-mfg-async";
			power-domains = <0x30 0x3>;
		};

		mfgsys-2d {
			compatible = "mediatek,mt8167-mfg-2d";
			power-domains = <0x30 0x4>;
		};

		mtee {
			compatible = "mediatek,mtee";
			clocks = <0x5 0x7b 0x5 0x65 0x38 0x5 0x16 0x0 0x38 0x0>;
			clock-names = "GCPU", "TRNG", "IMG_CLK", "SMI_COMMON", "IMG_SMI";
			pm-devs = <0x14 0x37>;
			pm-names = "isp", "disp";
		};

		mtgpufreq {
			compatible = "mediatek,mt8167-gpufreq";
			reg-vgpu-supply = <0x2a>;
		};

		pseudo-m4u {
			compatible = "mediatek,mt8167-pseudo-m4u";
			iommus = <0x56 0x1>;
		};

		pseudo-m4u-larb0 {
			compatible = "mediatek,mt8167-pseudo-port-m4u";
			mediatek,larbid = <0x0>;
			iommus = <0x56 0x0 0x56 0x1 0x56 0x2 0x56 0x3 0x56 0x4 0x56 0x5 0x56 0x5 0x56 0x6 0x56 0x7>;
		};

		pseudo-m4u-larb1 {
			compatible = "mediatek,mt8167-pseudo-port-m4u";
			mediatek,larbid = <0x1>;
			iommus = <0x56 0x8 0x56 0x9 0x56 0xa 0x56 0xb 0x56 0xc 0x56 0xd 0x56 0xe 0x56 0xf 0x56 0x10 0x56 0x11 0x56 0x12 0x56 0x13 0x56 0x14>;
		};

		pseudo-m4u-larb2 {
			compatible = "mediatek,mt8167-pseudo-port-m4u";
			mediatek,larbid = <0x2>;
			iommus = <0x56 0x15 0x56 0x16 0x56 0x17 0x56 0x18 0x56 0x19 0x56 0x1a 0x56 0x1b>;
		};
	};

	lcm {
		compatible = "mediatek,lcm";
	};

	zigbee {
		compatible = "mediatek,cc2530";
	};

	memory@00000000 {
		device_type = "memory";
		reg = <0x0 0x40000000 0x0 0x20000000>;
	};

	chosen {
		bootargs = "console=ttyS0,921600n1 root=/dev/ram initrd=0x44000200,0x200000";
	};

	cust_accel@0 {
		compatible = "mediatek,STK8BAXX";
		i2c_num = <0x1>;
		i2c_addr = <0x18 0x0 0x0 0x0>;
		direction = <0xe>;
		power_id = <0xffff>;
		power_vol = <0x0>;
		firlen = <0x2>;
		is_batch_supported = <0x0>;
	};

	fixedregulator@0 {
		compatible = "regulator-fixed";
		regulator-name = "mmc_io";
		regulator-min-microvolt = <0x1b7740>;
		regulator-max-microvolt = <0x1b7740>;
		regulator-always-on;
	};

	fixedregulator@1 {
		compatible = "regulator-fixed";
		regulator-name = "mmc_power";
		regulator-min-microvolt = <0x325aa0>;
		regulator-max-microvolt = <0x325aa0>;
		regulator-always-on;
	};

	mtcpufreq {
		compatible = "mediatek,mt8167-cpufreq";
		reg-ext-vproc-supply = <0x57>;
	};

	mt8167_audio_codec {
		compatible = "mediatek,mt8167-codec";
		clocks = <0x5 0x5b>;
		clock-names = "bus";
		mediatek,afe-regmap = <0x58>;
		mediatek,apmixedsys-regmap = <0x6>;
		mediatek,pwrap-regmap = <0x11>;
		mediatek,speaker-mode = <0x0>;
		mediatek,dmic-wire-mode = <0x1>;
		mediatek,headphone-cap-sel = <0x1>;
	};

	panel@0 {
		compatible = "kd,kd070d5450nha6";
		pinctrl-names = "default";
		pinctrl-0 = <0x59>;
		gpio_lcd_pwr = <0x12 0x2f 0x0>;
		gpio_lcd_rst = <0x12 0x42 0x0>;
		reg-lcm-supply = <0x5a>;
		status = "okay";
	};

	sound {
		compatible = "mediatek,mt8167-mt6392";
		mediatek,platform = <0x58>;
		mediatek,hp-spk-amp-warmup-time-us = <0x9c40>;
		mediatek,hp-spk-amp-shutdown-time-us = <0x9c40>;
		mediatek,ext-spk-amp-warmup-time-us = <0x13880>;
		mediatek,ext-spk-amp-shutdown-time-us = <0x9c40>;
		pinctrl-names = "default", "extamp_on", "extamp_off";
		pinctrl-0 = <0x5b>;
		pinctrl-1 = <0x5c>;
		pinctrl-2 = <0x5d>;
		status = "okay";
	};

	vibrator@0 {
		compatible = "mediatek,vibrator";
		vib_timer = <0x19>;
		vib_limit = <0x9>;
		vib_vol = <0x5>;
	};

	synaptics {
		compatible = "emdoor,synaptics_dsp";
		interrupt-parent = <0x12>;
		interrupts = <0x48 0x2>;
		pinctrl-names = "default", "dsp_rst_high", "dsp_rst_low", "dsp_pwr_high", "dsp_pwr_low", "led_pwr_high", "led_pwr_low";
		pinctrl-0 = <0x5e>;
		pinctrl-1 = <0x5f>;
		pinctrl-2 = <0x60>;
		pinctrl-3 = <0x61>;
		pinctrl-4 = <0x62>;
		pinctrl-5 = <0x63>;
		pinctrl-6 = <0x64>;
	};
};
